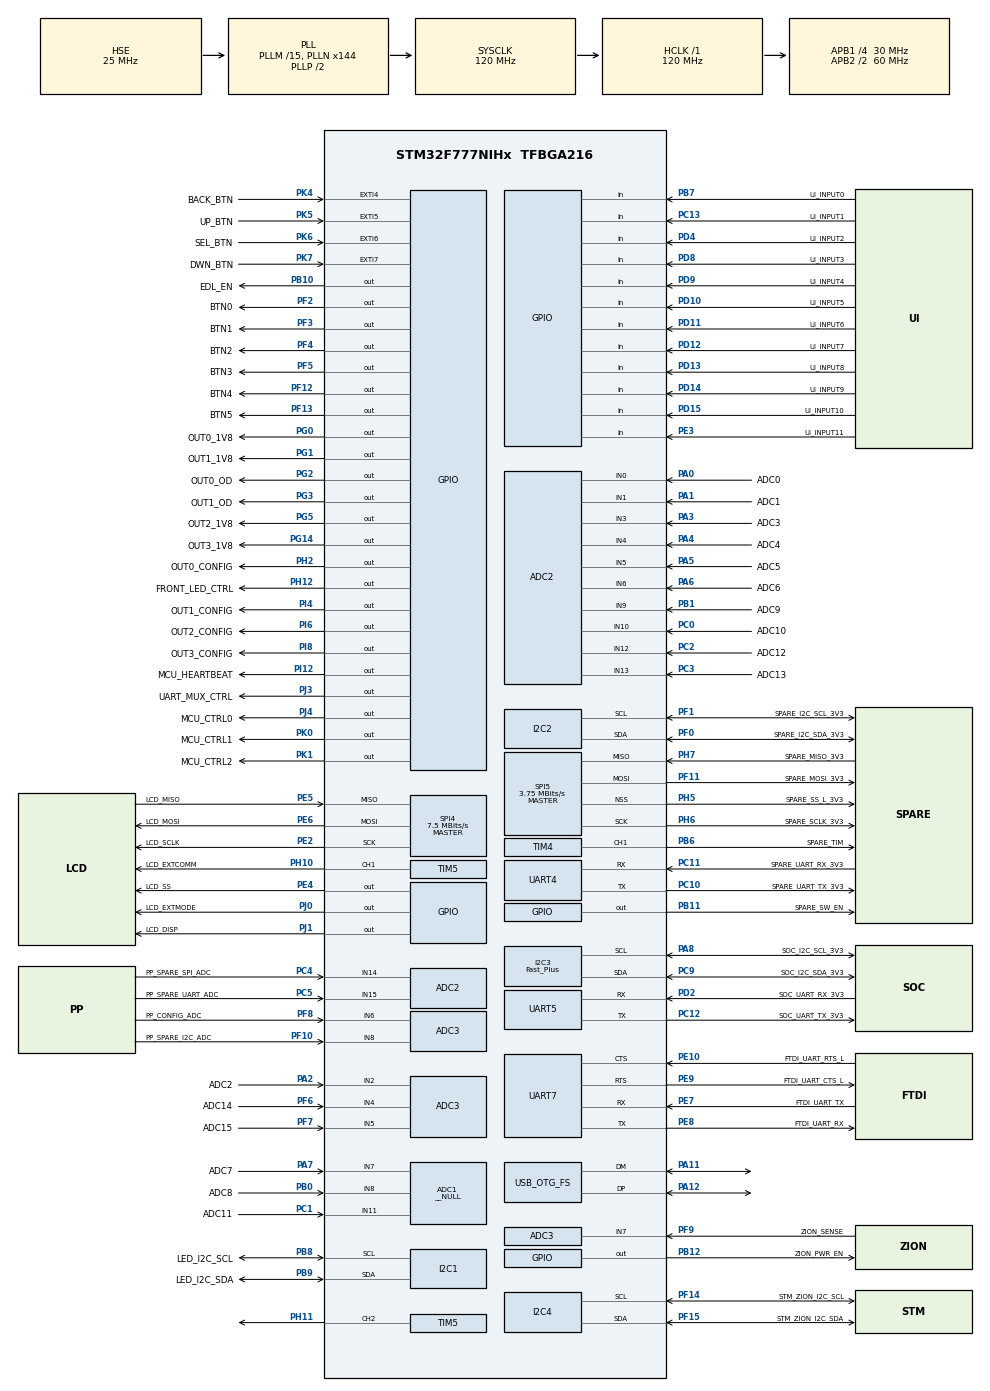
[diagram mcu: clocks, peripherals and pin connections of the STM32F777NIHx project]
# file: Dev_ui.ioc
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ADC1.Channel-0\#ChannelRegularConversion=ADC_CHANNEL_3
ADC1.Channel-1\#ChannelRegularConversion=ADC_CHANNEL_4
ADC1.Channel-10\#ChannelRegularConversion=ADC_CHANNEL_13
ADC1.Channel-2\#ChannelRegularConversion=ADC_CHANNEL_5
ADC1.Channel-3\#ChannelRegularConversion=ADC_CHANNEL_6
ADC1.Channel-4\#ChannelRegularConversion=ADC_CHANNEL_7
ADC1.Channel-5\#ChannelRegularConversion=ADC_CHANNEL_8
ADC1.Channel-6\#ChannelRegularConversion=ADC_CHANNEL_9
ADC1.Channel-7\#ChannelRegularConversion=ADC_CHANNEL_10
ADC1.Channel-8\#ChannelRegularConversion=ADC_CHANNEL_11
ADC1.Channel-9\#ChannelRegularConversion=ADC_CHANNEL_12
ADC1.ClockPrescaler=ADC_CLOCK_SYNC_PCLK_DIV4
ADC1.ContinuousConvMode=ENABLE
ADC1.DMAContinuousRequests=ENABLE
ADC1.InjNumberOfConversion=0
ADC1.Mode=__NULL
ADC1.NbrOfConversion=11
ADC1.NbrOfConversionFlag=1
ADC1.Rank-0\#ChannelRegularConversion=1
ADC1.Rank-1\#ChannelRegularConversion=2
ADC1.Rank-10\#ChannelRegularConversion=11
ADC1.Rank-2\#ChannelRegularConversion=3
ADC1.Rank-3\#ChannelRegularConversion=4
ADC1.Rank-4\#ChannelRegularConversion=5
ADC1.Rank-5\#ChannelRegularConversion=6
ADC1.Rank-6\#ChannelRegularConversion=7
ADC1.Rank-7\#ChannelRegularConversion=8
ADC1.Rank-8\#ChannelRegularConversion=9
ADC1.Rank-9\#ChannelRegularConversion=10
ADC1.SamplingTime-0\#ChannelRegularConversion=ADC_SAMPLETIME_480CYCLES
ADC1.SamplingTime-1\#ChannelRegularConversion=ADC_SAMPLETIME_480CYCLES
ADC1.SamplingTime-10\#ChannelRegularConversion=ADC_SAMPLETIME_480CYCLES
ADC1.SamplingTime-2\#ChannelRegularConversion=ADC_SAMPLETIME_480CYCLES
ADC1.SamplingTime-3\#ChannelRegularConversion=ADC_SAMPLETIME_480CYCLES
ADC1.SamplingTime-4\#ChannelRegularConversion=ADC_SAMPLETIME_480CYCLES
ADC1.SamplingTime-5\#ChannelRegularConversion=ADC_SAMPLETIME_480CYCLES
ADC1.SamplingTime-6\#ChannelRegularConversion=ADC_SAMPLETIME_480CYCLES
ADC1.SamplingTime-7\#ChannelRegularConversion=ADC_SAMPLETIME_480CYCLES
ADC1.SamplingTime-8\#ChannelRegularConversion=ADC_SAMPLETIME_480CYCLES
ADC1.SamplingTime-9\#ChannelRegularConversion=ADC_SAMPLETIME_480CYCLES
ADC1.ScanConvMode=ADC_SCAN_ENABLE
ADC1.master=1
ADC2.Channel-0\#ChannelRegularConversion=ADC_CHANNEL_0
ADC2.Channel-1\#ChannelRegularConversion=ADC_CHANNEL_1
ADC2.Channel-2\#ChannelRegularConversion=ADC_CHANNEL_14
ADC2.Channel-3\#ChannelRegularConversion=ADC_CHANNEL_15
ADC2.ClockPrescaler=ADC_CLOCK_SYNC_PCLK_DIV4
ADC2.ContinuousConvMode=ENABLE
ADC2.DMAContinuousRequests=ENABLE
ADC2.NbrOfConversion=4
ADC2.NbrOfConversionFlag=1
ADC2.Rank-0\#ChannelRegularConversion=1
ADC2.Rank-1\#ChannelRegularConversion=2
ADC2.Rank-2\#ChannelRegularConversion=3
ADC2.Rank-3\#ChannelRegularConversion=4
ADC2.SamplingTime-0\#ChannelRegularConversion=ADC_SAMPLETIME_480CYCLES
ADC2.SamplingTime-1\#ChannelRegularConversion=ADC_SAMPLETIME_480CYCLES
ADC2.SamplingTime-2\#ChannelRegularConversion=ADC_SAMPLETIME_480CYCLES
ADC2.SamplingTime-3\#ChannelRegularConversion=ADC_SAMPLETIME_480CYCLES
ADC2.ScanConvMode=ADC_SCAN_ENABLE
ADC3.Channel-0\#ChannelRegularConversion=ADC_CHANNEL_2
ADC3.Channel-1\#ChannelRegularConversion=ADC_CHANNEL_4
ADC3.Channel-2\#ChannelRegularConversion=ADC_CHANNEL_5
ADC3.Channel-3\#ChannelRegularConversion=ADC_CHANNEL_6
ADC3.Channel-4\#ChannelRegularConversion=ADC_CHANNEL_7
ADC3.Channel-5\#ChannelRegularConversion=ADC_CHANNEL_8
ADC3.ClockPrescaler=ADC_CLOCK_SYNC_PCLK_DIV4
ADC3.ContinuousConvMode=ENABLE
ADC3.DMAContinuousRequests=ENABLE
ADC3.NbrOfConversion=6
ADC3.NbrOfConversionFlag=1
ADC3.Rank-0\#ChannelRegularConversion=1
ADC3.Rank-1\#ChannelRegularConversion=2
ADC3.Rank-2\#ChannelRegularConversion=3
ADC3.Rank-3\#ChannelRegularConversion=4
ADC3.Rank-4\#ChannelRegularConversion=5
ADC3.Rank-5\#ChannelRegularConversion=6
ADC3.SamplingTime-0\#ChannelRegularConversion=ADC_SAMPLETIME_480CYCLES
ADC3.SamplingTime-1\#ChannelRegularConversion=ADC_SAMPLETIME_480CYCLES
ADC3.SamplingTime-2\#ChannelRegularConversion=ADC_SAMPLETIME_480CYCLES
ADC3.SamplingTime-3\#ChannelRegularConversion=ADC_SAMPLETIME_480CYCLES
ADC3.SamplingTime-4\#ChannelRegularConversion=ADC_SAMPLETIME_480CYCLES
ADC3.SamplingTime-5\#ChannelRegularConversion=ADC_SAMPLETIME_480CYCLES
ADC3.ScanConvMode=ADC_SCAN_ENABLE
ADC3.TwoSamplingDelay=ADC_TWOSAMPLINGDELAY_20CYCLES
Dma.ADC1.0.Direction=DMA_PERIPH_TO_MEMORY
Dma.ADC1.0.FIFOMode=DMA_FIFOMODE_DISABLE
Dma.ADC1.0.Instance=DMA2_Stream0
Dma.ADC1.0.MemDataAlignment=DMA_MDATAALIGN_WORD
Dma.ADC1.0.MemInc=DMA_MINC_ENABLE
Dma.ADC1.0.Mode=DMA_NORMAL
Dma.ADC1.0.PeriphDataAlignment=DMA_PDATAALIGN_WORD
Dma.ADC1.0.PeriphInc=DMA_PINC_DISABLE
Dma.ADC1.0.Priority=DMA_PRIORITY_LOW
Dma.ADC2.1.Direction=DMA_PERIPH_TO_MEMORY
Dma.ADC2.1.FIFOMode=DMA_FIFOMODE_DISABLE
Dma.ADC2.1.Instance=DMA2_Stream2
Dma.ADC2.1.MemDataAlignment=DMA_MDATAALIGN_WORD
Dma.ADC2.1.MemInc=DMA_MINC_ENABLE
Dma.ADC2.1.Mode=DMA_NORMAL
Dma.ADC2.1.PeriphDataAlignment=DMA_PDATAALIGN_WORD
Dma.ADC2.1.PeriphInc=DMA_PINC_DISABLE
Dma.ADC2.1.Priority=DMA_PRIORITY_LOW
Dma.ADC3.2.Direction=DMA_PERIPH_TO_MEMORY
Dma.ADC3.2.FIFOMode=DMA_FIFOMODE_DISABLE
Dma.ADC3.2.Instance=DMA2_Stream1
Dma.ADC3.2.MemDataAlignment=DMA_MDATAALIGN_WORD
Dma.ADC3.2.MemInc=DMA_MINC_ENABLE
Dma.ADC3.2.Mode=DMA_NORMAL
Dma.ADC3.2.PeriphDataAlignment=DMA_PDATAALIGN_WORD
Dma.ADC3.2.PeriphInc=DMA_PINC_DISABLE
Dma.ADC3.2.Priority=DMA_PRIORITY_LOW
Dma.Request0=ADC1
Dma.Request1=ADC2
Dma.Request2=ADC3
Dma.Request3=UART5_RX
Dma.Request4=UART7_RX
Dma.Request5=UART4_RX
Dma.UART4_RX.5.Direction=DMA_PERIPH_TO_MEMORY
Dma.UART4_RX.5.FIFOMode=DMA_FIFOMODE_DISABLE
Dma.UART4_RX.5.Instance=DMA1_Stream2
Dma.UART4_RX.5.MemDataAlignment=DMA_MDATAALIGN_BYTE
Dma.UART4_RX.5.MemInc=DMA_MINC_ENABLE
Dma.UART4_RX.5.Mode=DMA_CIRCULAR
Dma.UART4_RX.5.PeriphDataAlignment=DMA_PDATAALIGN_BYTE
Dma.UART4_RX.5.PeriphInc=DMA_PINC_DISABLE
Dma.UART4_RX.5.Priority=DMA_PRIORITY_LOW
Dma.UART5_RX.3.Direction=DMA_PERIPH_TO_MEMORY
Dma.UART5_RX.3.FIFOMode=DMA_FIFOMODE_DISABLE
Dma.UART5_RX.3.Instance=DMA1_Stream0
Dma.UART5_RX.3.MemDataAlignment=DMA_MDATAALIGN_BYTE
Dma.UART5_RX.3.MemInc=DMA_MINC_ENABLE
Dma.UART5_RX.3.Mode=DMA_CIRCULAR
Dma.UART5_RX.3.PeriphDataAlignment=DMA_PDATAALIGN_BYTE
Dma.UART5_RX.3.PeriphInc=DMA_PINC_DISABLE
Dma.UART5_RX.3.Priority=DMA_PRIORITY_LOW
Dma.UART7_RX.4.Direction=DMA_PERIPH_TO_MEMORY
Dma.UART7_RX.4.FIFOMode=DMA_FIFOMODE_DISABLE
Dma.UART7_RX.4.Instance=DMA1_Stream3
Dma.UART7_RX.4.MemDataAlignment=DMA_MDATAALIGN_BYTE
Dma.UART7_RX.4.MemInc=DMA_MINC_ENABLE
Dma.UART7_RX.4.Mode=DMA_CIRCULAR
Dma.UART7_RX.4.PeriphDataAlignment=DMA_PDATAALIGN_BYTE
Dma.UART7_RX.4.PeriphInc=DMA_PINC_DISABLE
Dma.UART7_RX.4.Priority=DMA_PRIORITY_LOW
FREERTOS.Events01=Fault_Events,Dynamic,NULL
FREERTOS.Tasks01=Heartbeat,32,256,startHeartbeat,Default,NULL,Dynamic,NULL,NULL;adcRead,9,256,startADCRead,Default,NULL,Dynamic,NULL,NULL;DatScreenBlink,26,5000,GetDaScreenBlink,Default,NULL,Dynamic,NULL,NULL;gpioInputRead,10,256,startGpioInputRead,Default,NULL,Dynamic,NULL,NULL;navigationTask,42,1000,startNavigationTask,Default,NULL,Dynamic,NULL,NULL;errorLEDs,13,1024,startErrorLEDs,Default,NULL,Dynamic,NULL,NULL;zionRead,41,2000,startZionRead,Default,NULL,Dynamic,NULL,NULL;bootButtons,22,1024,startBootButtons,Default,NULL,Dynamic,NULL,NULL;socUart,15,1024,startSocUart,Default,NULL,Dynamic,NULL,NULL;debugUart,15,512,startDebugUart,Default,NULL,Dynamic,NULL,NULL
FREERTOS.configTOTAL_HEAP_SIZE=150000
I2C1.Timing=0x007074AF
I2C2.Timing=0x007074AF
I2C3.I2C_Speed_Mode=I2C_Fast_Plus
I2C3.OwnAddress=76
I2C3.Speed=50
I2C3.Timing=0x100029FE
I2C4.Timing=0x007074AF
Mcu.Family=STM32F7
Mcu.Name=STM32F777NIHx
Mcu.Package=TFBGA216
NVIC.ADC_IRQn=true\:5\:0\:false\:false\:true\:true\:true\:true
NVIC.DMA1_Stream0_IRQn=true\:5\:0\:false\:false\:true\:true\:false\:true
NVIC.DMA1_Stream2_IRQn=true\:5\:0\:false\:false\:true\:true\:false\:true
NVIC.DMA1_Stream3_IRQn=true\:5\:0\:false\:false\:true\:true\:false\:true
NVIC.DMA2_Stream0_IRQn=true\:5\:0\:false\:false\:true\:true\:false\:true
NVIC.DMA2_Stream1_IRQn=true\:5\:0\:false\:false\:true\:true\:false\:true
NVIC.DMA2_Stream2_IRQn=true\:5\:0\:false\:false\:true\:true\:false\:true
NVIC.EXTI4_IRQn=true\:5\:0\:false\:false\:true\:true\:true\:true
NVIC.EXTI9_5_IRQn=true\:5\:0\:false\:false\:true\:true\:true\:true
NVIC.PriorityGroup=NVIC_PRIORITYGROUP_4
NVIC.SPI4_IRQn=true\:5\:0\:false\:false\:true\:true\:true\:true
NVIC.TIM6_DAC_IRQn=true\:0\:0\:false\:false\:true\:false\:false\:true
NVIC.TimeBase=TIM6_DAC_IRQn
NVIC.TimeBaseIP=TIM6
PA0/WKUP.GPIO_Label=ADC0
PA0/WKUP.Signal=ADCx_IN0
PA1.GPIO_Label=ADC1
PA1.Signal=ADCx_IN1
PA10.Signal=USB_OTG_FS_ID
PA11.Mode=Device_Only
PA11.Signal=USB_OTG_FS_DM
PA12.Mode=Device_Only
PA12.Signal=USB_OTG_FS_DP
PA13.Mode=JTAG_5_pins
PA13.Signal=SYS_JTMS-SWDIO
PA14.Mode=JTAG_5_pins
PA14.Signal=SYS_JTCK-SWCLK
PA15.Mode=JTAG_5_pins
PA15.Signal=SYS_JTDI
PA2.GPIO_Label=ADC2
PA2.Signal=ADCx_IN2
PA3.GPIO_Label=ADC3
PA3.GPIO_Mode=GPIO_MODE_ANALOG
PA3.GPIO_PuPd=GPIO_NOPULL
PA3.Signal=ADCx_IN3
PA4.GPIO_Label=ADC4
PA4.GPIO_Mode=GPIO_MODE_ANALOG
PA4.GPIO_PuPd=GPIO_NOPULL
PA4.Signal=ADCx_IN4
PA5.GPIO_Label=ADC5
PA5.GPIO_Mode=GPIO_MODE_ANALOG
PA5.GPIO_PuPd=GPIO_NOPULL
PA5.Signal=ADCx_IN5
PA6.GPIO_Label=ADC6
PA6.GPIO_Mode=GPIO_MODE_ANALOG
PA6.GPIO_PuPd=GPIO_NOPULL
PA6.Signal=ADCx_IN6
PA7.GPIO_Label=ADC7
PA7.Signal=ADCx_IN7
PA8.GPIO_Label=SOC_I2C_SCL_3V3
PA8.GPIO_Mode=GPIO_MODE_AF_OD
PA8.GPIO_PuPdOD=GPIO_PULLUP
PA8.GPIO_Speed=GPIO_SPEED_FREQ_VERY_HIGH
PA8.Mode=I2C
PA8.Signal=I2C3_SCL
PB0.GPIO_Label=ADC8
PB0.Signal=ADCx_IN8
PB1.GPIO_Label=ADC9
PB1.GPIO_Mode=GPIO_MODE_ANALOG
PB1.GPIO_PuPd=GPIO_NOPULL
PB1.Signal=ADCx_IN9
PB10.GPIO_Label=EDL_EN
PB10.Signal=GPIO_Output
PB11.GPIO_Label=SPARE_SW_EN
PB11.Signal=GPIO_Output
PB12.GPIO_Label=ZION_PWR_EN
PB12.Signal=GPIO_Output
PB3.Mode=JTAG_5_pins
PB3.Signal=SYS_JTDO-SWO
PB4.Mode=JTAG_5_pins
PB4.Signal=SYS_JTRST
PB6.GPIO_Label=SPARE_TIM
PB6.Signal=S_TIM4_CH1
PB7.GPIO_Label=UI_INPUT0
PB7.GPIO_Mode=GPIO_MODE_INPUT
PB7.GPIO_PuPd=GPIO_NOPULL
PB7.Signal=GPIO_Input
PB8.GPIO_Label=LED_I2C_SCL
PB8.GPIO_Mode=GPIO_MODE_AF_OD
PB8.GPIO_PuPdOD=GPIO_PULLUP
PB8.GPIO_Speed=GPIO_SPEED_FREQ_VERY_HIGH
PB8.Mode=I2C
PB8.Signal=I2C1_SCL
PB9.GPIO_Label=LED_I2C_SDA
PB9.GPIO_Mode=GPIO_MODE_AF_OD
PB9.GPIO_PuPdOD=GPIO_PULLUP
PB9.GPIO_Speed=GPIO_SPEED_FREQ_VERY_HIGH
PB9.Mode=I2C
PB9.Signal=I2C1_SDA
PC0.GPIO_Label=ADC10
PC0.GPIO_Mode=GPIO_MODE_ANALOG
PC0.GPIO_PuPd=GPIO_NOPULL
PC0.Signal=ADCx_IN10
PC1.GPIO_Label=ADC11
PC1.Signal=ADCx_IN11
PC10.GPIO_Label=SPARE_UART_TX_3V3
PC10.GPIO_ModeDefaultPP=GPIO_MODE_AF_PP
PC10.GPIO_PuPd=GPIO_NOPULL
PC10.GPIO_Speed=GPIO_SPEED_FREQ_VERY_HIGH
PC10.Mode=Asynchronous
PC10.Signal=UART4_TX
PC11.GPIO_Label=SPARE_UART_RX_3V3
PC11.GPIO_ModeDefaultPP=GPIO_MODE_AF_PP
PC11.GPIO_PuPd=GPIO_NOPULL
PC11.GPIO_Speed=GPIO_SPEED_FREQ_VERY_HIGH
PC11.Mode=Asynchronous
PC11.Signal=UART4_RX
PC12.GPIO_Label=SOC_UART_TX_3V3
PC12.GPIO_ModeDefaultPP=GPIO_MODE_AF_PP
PC12.GPIO_PuPd=GPIO_NOPULL
PC12.GPIO_Speed=GPIO_SPEED_FREQ_VERY_HIGH
PC12.Mode=Asynchronous
PC12.Signal=UART5_TX
PC13.GPIO_Label=UI_INPUT1
PC13.GPIO_Mode=GPIO_MODE_INPUT
PC13.GPIO_PuPd=GPIO_NOPULL
PC13.Signal=GPIO_Input
PC14/OSC32_IN.Mode=LSE-External-Oscillator
PC14/OSC32_IN.Signal=RCC_OSC32_IN
PC15/OSC32_OUT.Mode=LSE-External-Oscillator
PC15/OSC32_OUT.Signal=RCC_OSC32_OUT
PC2.GPIO_Label=ADC12
PC2.GPIO_Mode=GPIO_MODE_ANALOG
PC2.GPIO_PuPd=GPIO_NOPULL
PC2.Signal=ADCx_IN12
PC3.GPIO_Label=ADC13
PC3.GPIO_Mode=GPIO_MODE_ANALOG
PC3.GPIO_PuPd=GPIO_NOPULL
PC3.Signal=ADCx_IN13
PC4.GPIO_Label=PP_SPARE_SPI_ADC
PC4.Signal=ADCx_IN14
PC5.GPIO_Label=PP_SPARE_UART_ADC
PC5.Signal=ADCx_IN15
PC9.GPIO_Label=SOC_I2C_SDA_3V3
PC9.GPIO_Mode=GPIO_MODE_AF_OD
PC9.GPIO_PuPdOD=GPIO_PULLUP
PC9.GPIO_Speed=GPIO_SPEED_FREQ_VERY_HIGH
PC9.Mode=I2C
PC9.Signal=I2C3_SDA
PD10.GPIO_Label=UI_INPUT5
PD10.GPIO_Mode=GPIO_MODE_INPUT
PD10.GPIO_PuPd=GPIO_NOPULL
PD10.Signal=GPIO_Input
PD11.GPIO_Label=UI_INPUT6
PD11.GPIO_Mode=GPIO_MODE_INPUT
PD11.GPIO_PuPd=GPIO_NOPULL
PD11.Signal=GPIO_Input
PD12.GPIO_Label=UI_INPUT7
PD12.GPIO_Mode=GPIO_MODE_INPUT
PD12.GPIO_PuPd=GPIO_NOPULL
PD12.Signal=GPIO_Input
PD13.GPIO_Label=UI_INPUT8
PD13.GPIO_Mode=GPIO_MODE_INPUT
PD13.GPIO_PuPd=GPIO_NOPULL
PD13.Signal=GPIO_Input
PD14.GPIO_Label=UI_INPUT9
PD14.GPIO_Mode=GPIO_MODE_INPUT
PD14.GPIO_PuPd=GPIO_NOPULL
PD14.Signal=GPIO_Input
PD15.GPIO_Label=UI_INPUT10
PD15.GPIO_Mode=GPIO_MODE_INPUT
PD15.GPIO_PuPd=GPIO_NOPULL
PD15.Signal=GPIO_Input
PD2.GPIO_Label=SOC_UART_RX_3V3
PD2.GPIO_ModeDefaultPP=GPIO_MODE_AF_PP
PD2.GPIO_PuPd=GPIO_NOPULL
PD2.GPIO_Speed=GPIO_SPEED_FREQ_VERY_HIGH
PD2.Mode=Asynchronous
PD2.Signal=UART5_RX
PD4.GPIO_Label=UI_INPUT2
PD4.GPIO_Mode=GPIO_MODE_INPUT
PD4.GPIO_PuPd=GPIO_NOPULL
PD4.Signal=GPIO_Input
PD8.GPIO_Label=UI_INPUT3
PD8.GPIO_Mode=GPIO_MODE_INPUT
PD8.GPIO_PuPd=GPIO_NOPULL
PD8.Signal=GPIO_Input
PD9.GPIO_Label=UI_INPUT4
PD9.GPIO_Mode=GPIO_MODE_INPUT
PD9.GPIO_PuPd=GPIO_NOPULL
PD9.Signal=GPIO_Input
PE10.GPIO_Label=FTDI_UART_RTS_L
PE10.GPIO_Mode=GPIO_MODE_AF_PP
PE10.GPIO_PuPd=GPIO_NOPULL
PE10.GPIO_Speed=GPIO_SPEED_FREQ_VERY_HIGH
PE10.Mode=CTS_RTS
PE10.Signal=UART7_CTS
PE2.GPIO_Label=LCD_SCLK
PE2.GPIO_Mode=GPIO_MODE_AF_PP
PE2.GPIO_PuPd=GPIO_NOPULL
PE2.GPIO_Speed=GPIO_SPEED_FREQ_VERY_HIGH
PE2.Mode=Full_Duplex_Master
PE2.Signal=SPI4_SCK
PE3.GPIO_Label=UI_INPUT11
PE3.GPIO_Mode=GPIO_MODE_INPUT
PE3.GPIO_PuPd=GPIO_NOPULL
PE3.Signal=GPIO_Input
PE4.GPIO_Label=LCD_SS
PE4.GPIO_Speed=GPIO_SPEED_FREQ_HIGH
PE4.Signal=GPIO_Output
PE5.GPIO_Label=LCD_MISO
PE5.GPIO_Mode=GPIO_MODE_AF_PP
PE5.GPIO_PuPd=GPIO_NOPULL
PE5.GPIO_Speed=GPIO_SPEED_FREQ_VERY_HIGH
PE5.Mode=Full_Duplex_Master
PE5.Signal=SPI4_MISO
PE6.GPIO_Label=LCD_MOSI
PE6.GPIO_Mode=GPIO_MODE_AF_PP
PE6.GPIO_PuPd=GPIO_NOPULL
PE6.GPIO_Speed=GPIO_SPEED_FREQ_VERY_HIGH
PE6.Mode=Full_Duplex_Master
PE6.Signal=SPI4_MOSI
PE7.GPIO_Label=FTDI_UART_TX
PE7.GPIO_ModeDefaultPP=GPIO_MODE_AF_PP
PE7.GPIO_PuPd=GPIO_NOPULL
PE7.GPIO_Speed=GPIO_SPEED_FREQ_VERY_HIGH
PE7.Mode=Asynchronous
PE7.Signal=UART7_RX
PE8.GPIO_Label=FTDI_UART_RX
PE8.GPIO_ModeDefaultPP=GPIO_MODE_AF_PP
PE8.GPIO_PuPd=GPIO_NOPULL
PE8.GPIO_Speed=GPIO_SPEED_FREQ_VERY_HIGH
PE8.Mode=Asynchronous
PE8.Signal=UART7_TX
PE9.GPIO_Label=FTDI_UART_CTS_L
PE9.GPIO_Mode=GPIO_MODE_AF_PP
PE9.GPIO_PuPd=GPIO_NOPULL
PE9.GPIO_Speed=GPIO_SPEED_FREQ_VERY_HIGH
PE9.Mode=CTS_RTS
PE9.Signal=UART7_RTS
PF0.GPIO_Label=SPARE_I2C_SDA_3V3
PF0.GPIO_Mode=GPIO_MODE_AF_OD
PF0.GPIO_PuPdOD=GPIO_PULLUP
PF0.GPIO_Speed=GPIO_SPEED_FREQ_VERY_HIGH
PF0.Mode=I2C
PF0.Signal=I2C2_SDA
PF1.GPIO_Label=SPARE_I2C_SCL_3V3
PF1.GPIO_Mode=GPIO_MODE_AF_OD
PF1.GPIO_PuPdOD=GPIO_PULLUP
PF1.GPIO_Speed=GPIO_SPEED_FREQ_VERY_HIGH
PF1.Mode=I2C
PF1.Signal=I2C2_SCL
PF10.GPIO_Label=PP_SPARE_I2C_ADC
PF10.Mode=IN8
PF10.Signal=ADC3_IN8
PF11.GPIO_Label=SPARE_MOSI_3V3
PF11.GPIO_Mode=GPIO_MODE_AF_PP
PF11.GPIO_PuPd=GPIO_NOPULL
PF11.GPIO_Speed=GPIO_SPEED_FREQ_VERY_HIGH
PF11.Mode=Full_Duplex_Master
PF11.Signal=SPI5_MOSI
PF12.GPIO_Label=BTN4
PF12.GPIO_ModeDefaultOutputPP=GPIO_MODE_OUTPUT_PP
PF12.GPIO_PuPd=GPIO_NOPULL
PF12.GPIO_Speed=GPIO_SPEED_FREQ_LOW
PF12.PinState=GPIO_PIN_RESET
PF12.Signal=GPIO_Output
PF13.GPIO_Label=BTN5
PF13.GPIO_ModeDefaultOutputPP=GPIO_MODE_OUTPUT_PP
PF13.GPIO_PuPd=GPIO_NOPULL
PF13.GPIO_Speed=GPIO_SPEED_FREQ_LOW
PF13.PinState=GPIO_PIN_RESET
PF13.Signal=GPIO_Output
PF14.GPIO_Label=STM_ZION_I2C_SCL
PF14.GPIO_Mode=GPIO_MODE_AF_OD
PF14.GPIO_PuPdOD=GPIO_PULLUP
PF14.GPIO_Speed=GPIO_SPEED_FREQ_VERY_HIGH
PF14.Mode=I2C
PF14.Signal=I2C4_SCL
PF15.GPIO_Label=STM_ZION_I2C_SDA
PF15.GPIO_Mode=GPIO_MODE_AF_OD
PF15.GPIO_PuPdOD=GPIO_PULLUP
PF15.GPIO_Speed=GPIO_SPEED_FREQ_VERY_HIGH
PF15.Mode=I2C
PF15.Signal=I2C4_SDA
PF2.GPIO_Label=BTN0
PF2.GPIO_ModeDefaultOutputPP=GPIO_MODE_OUTPUT_PP
PF2.GPIO_PuPd=GPIO_NOPULL
PF2.GPIO_Speed=GPIO_SPEED_FREQ_LOW
PF2.PinState=GPIO_PIN_RESET
PF2.Signal=GPIO_Output
PF3.GPIO_Label=BTN1
PF3.GPIO_ModeDefaultOutputPP=GPIO_MODE_OUTPUT_PP
PF3.GPIO_PuPd=GPIO_NOPULL
PF3.GPIO_Speed=GPIO_SPEED_FREQ_LOW
PF3.PinState=GPIO_PIN_RESET
PF3.Signal=GPIO_Output
PF4.GPIO_Label=BTN2
PF4.GPIO_ModeDefaultOutputPP=GPIO_MODE_OUTPUT_PP
PF4.GPIO_PuPd=GPIO_NOPULL
PF4.GPIO_Speed=GPIO_SPEED_FREQ_LOW
PF4.PinState=GPIO_PIN_RESET
PF4.Signal=GPIO_Output
PF5.GPIO_Label=BTN3
PF5.GPIO_ModeDefaultOutputPP=GPIO_MODE_OUTPUT_PP
PF5.GPIO_PuPd=GPIO_NOPULL
PF5.GPIO_Speed=GPIO_SPEED_FREQ_LOW
PF5.PinState=GPIO_PIN_RESET
PF5.Signal=GPIO_Output
PF6.GPIO_Label=ADC14
PF6.GPIO_Mode=GPIO_MODE_ANALOG
PF6.GPIO_PuPd=GPIO_NOPULL
PF6.Mode=IN4
PF6.Signal=ADC3_IN4
PF7.GPIO_Label=ADC15
PF7.GPIO_Mode=GPIO_MODE_ANALOG
PF7.GPIO_PuPd=GPIO_NOPULL
PF7.Mode=IN5
PF7.Signal=ADC3_IN5
PF8.GPIO_Label=PP_CONFIG_ADC
PF8.GPIO_Mode=GPIO_MODE_ANALOG
PF8.GPIO_PuPd=GPIO_NOPULL
PF8.Mode=IN6
PF8.Signal=ADC3_IN6
PF9.GPIO_Label=ZION_SENSE
PF9.GPIO_Mode=GPIO_MODE_ANALOG
PF9.GPIO_PuPd=GPIO_NOPULL
PF9.Mode=IN7
PF9.Signal=ADC3_IN7
PG0.GPIO_Label=OUT0_1V8
PG0.GPIO_ModeDefaultOutputPP=GPIO_MODE_OUTPUT_PP
PG0.GPIO_PuPd=GPIO_NOPULL
PG0.GPIO_Speed=GPIO_SPEED_FREQ_LOW
PG0.PinState=GPIO_PIN_RESET
PG0.Signal=GPIO_Output
PG1.GPIO_Label=OUT1_1V8
PG1.GPIO_ModeDefaultOutputPP=GPIO_MODE_OUTPUT_PP
PG1.GPIO_PuPd=GPIO_NOPULL
PG1.GPIO_Speed=GPIO_SPEED_FREQ_LOW
PG1.PinState=GPIO_PIN_RESET
PG1.Signal=GPIO_Output
PG14.GPIO_Label=OUT3_1V8
PG14.GPIO_ModeDefaultOutputPP=GPIO_MODE_OUTPUT_PP
PG14.GPIO_PuPd=GPIO_NOPULL
PG14.GPIO_Speed=GPIO_SPEED_FREQ_LOW
PG14.PinState=GPIO_PIN_RESET
PG14.Signal=GPIO_Output
PG2.GPIO_Label=OUT0_OD
PG2.Signal=GPIO_Output
PG3.GPIO_Label=OUT1_OD
PG3.Signal=GPIO_Output
PG5.GPIO_Label=OUT2_1V8
PG5.GPIO_ModeDefaultOutputPP=GPIO_MODE_OUTPUT_PP
PG5.GPIO_PuPd=GPIO_NOPULL
PG5.GPIO_Speed=GPIO_SPEED_FREQ_LOW
PG5.PinState=GPIO_PIN_RESET
PG5.Signal=GPIO_Output
PH0/OSC_IN.Mode=HSE-External-Oscillator
PH0/OSC_IN.Signal=RCC_OSC_IN
PH1/OSC_OUT.Mode=HSE-External-Oscillator
PH1/OSC_OUT.Signal=RCC_OSC_OUT
PH10.GPIO_Label=LCD_EXTCOMM
PH10.Signal=S_TIM5_CH1
PH11.Signal=S_TIM5_CH2
PH12.GPIO_Label=FRONT_LED_CTRL
PH12.Signal=GPIO_Output
PH2.GPIO_Label=OUT0_CONFIG
PH2.GPIO_ModeDefaultOutputPP=GPIO_MODE_OUTPUT_PP
PH2.GPIO_PuPd=GPIO_NOPULL
PH2.GPIO_Speed=GPIO_SPEED_FREQ_LOW
PH2.PinState=GPIO_PIN_RESET
PH2.Signal=GPIO_Output
PH5.GPIO_Label=SPARE_SS_L_3V3
PH5.GPIO_Mode=GPIO_MODE_AF_PP
PH5.GPIO_PuPd=GPIO_NOPULL
PH5.GPIO_Speed=GPIO_SPEED_FREQ_VERY_HIGH
PH5.Mode=NSS_Signal_Hard_Output
PH5.Signal=SPI5_NSS
PH6.GPIO_Label=SPARE_SCLK_3V3
PH6.GPIO_Mode=GPIO_MODE_AF_PP
PH6.GPIO_PuPd=GPIO_NOPULL
PH6.GPIO_Speed=GPIO_SPEED_FREQ_VERY_HIGH
PH6.Mode=Full_Duplex_Master
PH6.Signal=SPI5_SCK
PH7.GPIO_Label=SPARE_MISO_3V3
PH7.GPIO_Mode=GPIO_MODE_AF_PP
PH7.GPIO_PuPd=GPIO_NOPULL
PH7.GPIO_Speed=GPIO_SPEED_FREQ_VERY_HIGH
PH7.Mode=Full_Duplex_Master
PH7.Signal=SPI5_MISO
PI12.GPIO_Label=MCU_HEARTBEAT
PI12.GPIO_ModeDefaultOutputPP=GPIO_MODE_OUTPUT_PP
PI12.GPIO_PuPd=GPIO_NOPULL
PI12.GPIO_Speed=GPIO_SPEED_FREQ_LOW
PI12.PinState=GPIO_PIN_RESET
PI12.Signal=GPIO_Output
PI4.GPIO_Label=OUT1_CONFIG
PI4.GPIO_ModeDefaultOutputPP=GPIO_MODE_OUTPUT_PP
PI4.GPIO_PuPd=GPIO_NOPULL
PI4.GPIO_Speed=GPIO_SPEED_FREQ_LOW
PI4.PinState=GPIO_PIN_RESET
PI4.Signal=GPIO_Output
PI6.GPIO_Label=OUT2_CONFIG
PI6.GPIO_ModeDefaultOutputPP=GPIO_MODE_OUTPUT_PP
PI6.GPIO_PuPd=GPIO_NOPULL
PI6.GPIO_Speed=GPIO_SPEED_FREQ_LOW
PI6.PinState=GPIO_PIN_RESET
PI6.Signal=GPIO_Output
PI8.GPIO_Label=OUT3_CONFIG
PI8.GPIO_ModeDefaultOutputPP=GPIO_MODE_OUTPUT_PP
PI8.GPIO_PuPd=GPIO_NOPULL
PI8.GPIO_Speed=GPIO_SPEED_FREQ_LOW
PI8.PinState=GPIO_PIN_RESET
PI8.Signal=GPIO_Output
PJ0.GPIO_Label=LCD_EXTMODE
PJ0.GPIO_ModeDefaultOutputPP=GPIO_MODE_OUTPUT_PP
PJ0.GPIO_PuPd=GPIO_NOPULL
PJ0.GPIO_Speed=GPIO_SPEED_FREQ_LOW
PJ0.PinState=GPIO_PIN_RESET
PJ0.Signal=GPIO_Output
PJ1.GPIO_Label=LCD_DISP
PJ1.GPIO_ModeDefaultOutputPP=GPIO_MODE_OUTPUT_PP
PJ1.GPIO_PuPd=GPIO_NOPULL
PJ1.GPIO_Speed=GPIO_SPEED_FREQ_LOW
PJ1.PinState=GPIO_PIN_RESET
PJ1.Signal=GPIO_Output
PJ3.GPIO_Label=UART_MUX_CTRL
PJ3.GPIO_ModeDefaultOutputPP=GPIO_MODE_OUTPUT_PP
PJ3.GPIO_PuPd=GPIO_NOPULL
PJ3.GPIO_Speed=GPIO_SPEED_FREQ_LOW
PJ3.PinState=GPIO_PIN_RESET
PJ3.Signal=GPIO_Output
PJ4.GPIO_Label=MCU_CTRL0
PJ4.GPIO_ModeDefaultOutputPP=GPIO_MODE_OUTPUT_PP
PJ4.GPIO_PuPd=GPIO_NOPULL
PJ4.GPIO_Speed=GPIO_SPEED_FREQ_LOW
PJ4.PinState=GPIO_PIN_RESET
PJ4.Signal=GPIO_Output
PK0.GPIO_Label=MCU_CTRL1
PK0.GPIO_ModeDefaultOutputPP=GPIO_MODE_OUTPUT_PP
PK0.GPIO_PuPd=GPIO_NOPULL
PK0.GPIO_Speed=GPIO_SPEED_FREQ_LOW
PK0.PinState=GPIO_PIN_RESET
PK0.Signal=GPIO_Output
PK1.GPIO_Label=MCU_CTRL2
PK1.GPIO_ModeDefaultOutputPP=GPIO_MODE_OUTPUT_PP
PK1.GPIO_PuPd=GPIO_NOPULL
PK1.GPIO_Speed=GPIO_SPEED_FREQ_LOW
PK1.PinState=GPIO_PIN_RESET
PK1.Signal=GPIO_Output
PK4.GPIO_Label=BACK_BTN
PK4.GPIO_ModeDefaultEXTI=GPIO_MODE_IT_FALLING
PK4.Signal=GPXTI4
PK5.GPIO_Label=UP_BTN
PK5.GPIO_ModeDefaultEXTI=GPIO_MODE_IT_FALLING
PK5.Signal=GPXTI5
PK6.GPIO_Label=SEL_BTN
PK6.GPIO_ModeDefaultEXTI=GPIO_MODE_IT_FALLING
PK6.Signal=GPXTI6
PK7.GPIO_Label=DWN_BTN
PK7.GPIO_ModeDefaultEXTI=GPIO_MODE_IT_FALLING
PK7.Signal=GPXTI7
ProjectManager.HeapSize=0x200
ProjectManager.StackSize=0x400
ProjectManager.TargetToolchain=STM32CubeIDE
RCC.AHBFreq_Value=120000000
RCC.APB1CLKDivider=RCC_HCLK_DIV4
RCC.APB1Freq_Value=30000000
RCC.APB1TimFreq_Value=60000000
RCC.APB2CLKDivider=RCC_HCLK_DIV2
RCC.APB2Freq_Value=60000000
RCC.APB2TimFreq_Value=120000000
RCC.CortexFreq_Value=120000000
RCC.HCLKFreq_Value=120000000
RCC.HSE_VALUE=25000000
RCC.HSI_VALUE=16000000
RCC.PLLM=15
RCC.PLLN=144
RCC.PLLQ=5
RCC.PLLSAIN=60
RCC.RTCClockSelection=RCC_RTCCLKSOURCE_LSE
RCC.SYSCLKFreq_VALUE=120000000
RCC.SYSCLKSource=RCC_SYSCLKSOURCE_PLLCLK
RCC.USBFreq_Value=48000000
RCC.VCOOutputFreq_Value=240000000
SH.ADCx_IN0.0=ADC2_IN0,IN0
SH.ADCx_IN1.0=ADC2_IN1,IN1
SH.ADCx_IN10.0=ADC2_IN10,IN10
SH.ADCx_IN10.1=ADC1_IN10,IN10
SH.ADCx_IN10.2=ADC3_IN10,IN10
SH.ADCx_IN11.0=ADC2_IN11
SH.ADCx_IN11.1=ADC3_IN11
SH.ADCx_IN11.2=ADC1_IN11,IN11
SH.ADCx_IN12.0=ADC2_IN12,IN12
SH.ADCx_IN12.1=ADC1_IN12,IN12
SH.ADCx_IN12.2=ADC3_IN12,IN12
SH.ADCx_IN13.0=ADC2_IN13,IN13
SH.ADCx_IN13.1=ADC1_IN13,IN13
SH.ADCx_IN13.2=ADC3_IN13,IN13
SH.ADCx_IN14.0=ADC2_IN14,IN14
SH.ADCx_IN15.0=ADC2_IN15,IN15
SH.ADCx_IN2.0=ADC3_IN2,IN2
SH.ADCx_IN3.0=ADC2_IN3,IN3
SH.ADCx_IN3.1=ADC1_IN3,IN3
SH.ADCx_IN3.2=ADC3_IN3,IN3
SH.ADCx_IN4.0=ADC2_IN4,IN4
SH.ADCx_IN4.1=ADC1_IN4,IN4
SH.ADCx_IN5.0=ADC2_IN5,IN5
SH.ADCx_IN5.1=ADC1_IN5,IN5
SH.ADCx_IN6.0=ADC2_IN6,IN6
SH.ADCx_IN6.1=ADC1_IN6,IN6
SH.ADCx_IN7.0=ADC1_IN7,IN7
SH.ADCx_IN8.0=ADC1_IN8,IN8
SH.ADCx_IN9.0=ADC2_IN9,IN9
SH.ADCx_IN9.1=ADC1_IN9,IN9
SH.S_TIM4_CH1.0=TIM4_CH1,PWM Generation1 CH1
SH.S_TIM5_CH1.0=TIM5_CH1,PWM Generation1 CH1
SH.S_TIM5_CH2.0=TIM5_CH2,PWM Generation2 CH2
SPI4.BaudRatePrescaler=SPI_BAUDRATEPRESCALER_8
SPI4.CalculateBaudRate=7.5 MBits/s
SPI4.DataSize=SPI_DATASIZE_8BIT
SPI4.Direction=SPI_DIRECTION_2LINES
SPI4.Mode=SPI_MODE_MASTER
SPI4.NSSPMode=SPI_NSS_PULSE_DISABLE
SPI4.VirtualType=VM_MASTER
SPI5.BaudRatePrescaler=SPI_BAUDRATEPRESCALER_16
SPI5.CalculateBaudRate=3.75 MBits/s
SPI5.DataSize=SPI_DATASIZE_8BIT
SPI5.Direction=SPI_DIRECTION_2LINES
SPI5.Mode=SPI_MODE_MASTER
SPI5.NSSPMode=SPI_NSS_PULSE_DISABLE
SPI5.VirtualNSS=VM_NSSHARD
SPI5.VirtualType=VM_MASTER
TIM4.Channel-PWM\ Generation1\ CH1=TIM_CHANNEL_1
TIM5.Channel-PWM\ Generation1\ CH1=TIM_CHANNEL_1
TIM5.Channel-PWM\ Generation2\ CH2=TIM_CHANNEL_2
USB_OTG_FS.VirtualMode=Device_Only
VP_FREERTOS_VS_CMSIS_V2.Mode=CMSIS_V2
VP_RTC_VS_RTC_Activate.Mode=RTC_Enabled
VP_SYS_VS_tim6.Mode=TIM6
VP_TIM4_VS_ClockSourceINT.Mode=Internal
VP_TIM5_VS_ClockSourceINT.Mode=Internal
board=custom

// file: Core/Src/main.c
/* USER CODE BEGIN Header */
/**
  ******************************************************************************
  * @file           : main.c
  * @brief          : Main program body
  ******************************************************************************
  * @attention
  *
  * <h2><center>&copy; Copyright (c) 2021 STMicroelectronics.
  * All rights reserved.</center></h2>
  *
  * This software component is licensed by ST under BSD 3-Clause license,
  * the "License"; You may not use this file except in compliance with the
  * License. You may obtain a copy of the License at:
  *                        opensource.org/licenses/BSD-3-Clause
  *
  ******************************************************************************
  */
/* USER CODE END Header */
#include "main.h"
#include "cmsis_os.h"

/* USER CODE BEGIN PTD */
//ADC Definitions
#define ADC_BUF_LEN 			5000
#define ADC_AVG_COUNT 			20

//UART Buffer Length Definitions
#define SOC_UART_BUF_LEN		1000
#define SPARE_UART_BUF_LEN		200
#define DEBUG_UART_BUF_LEN		200

/* USER CODE END PTD */

ADC_HandleTypeDef hadc1;
ADC_HandleTypeDef hadc2;
ADC_HandleTypeDef hadc3;
DMA_HandleTypeDef hdma_adc1;
DMA_HandleTypeDef hdma_adc2;
DMA_HandleTypeDef hdma_adc3;

I2C_HandleTypeDef hi2c1;
I2C_HandleTypeDef hi2c2;
I2C_HandleTypeDef hi2c3;
I2C_HandleTypeDef hi2c4;

RTC_HandleTypeDef hrtc;

SPI_HandleTypeDef hspi4;
SPI_HandleTypeDef hspi5;

TIM_HandleTypeDef htim4;
TIM_HandleTypeDef htim5;

UART_HandleTypeDef huart4;
UART_HandleTypeDef huart5;
UART_HandleTypeDef huart7;
DMA_HandleTypeDef hdma_uart4_rx;
DMA_HandleTypeDef hdma_uart5_rx;
DMA_HandleTypeDef hdma_uart7_rx;

PCD_HandleTypeDef hpcd_USB_OTG_FS;

/* Definitions for Heartbeat */
osThreadId_t HeartbeatHandle;
const osThreadAttr_t Heartbeat_attributes = {
  .name = "Heartbeat",
  .priority = (osPriority_t) osPriorityAboveNormal,
  .stack_size = 256 * 4
};
/* Definitions for adcRead */
osThreadId_t adcReadHandle;
const osThreadAttr_t adcRead_attributes = {
  .name = "adcRead",
  .priority = (osPriority_t) osPriorityLow1,
  .stack_size = 256 * 4
};
/* Definitions for DatScreenBlink */
osThreadId_t DatScreenBlinkHandle;
const osThreadAttr_t DatScreenBlink_attributes = {
  .name = "DatScreenBlink",
  .priority = (osPriority_t) osPriorityNormal2,
  .stack_size = 5000 * 4
};
/* Definitions for gpioInputRead */
osThreadId_t gpioInputReadHandle;
const osThreadAttr_t gpioInputRead_attributes = {
  .name = "gpioInputRead",
  .priority = (osPriority_t) osPriorityLow2,
  .stack_size = 256 * 4
};
/* Definitions for navigationTask */
osThreadId_t navigationTaskHandle;
const osThreadAttr_t navigationTask_attributes = {
  .name = "navigationTask",
  .priority = (osPriority_t) osPriorityHigh2,
  .stack_size = 1000 * 4
};
/* Definitions for errorLEDs */
osThreadId_t errorLEDsHandle;
const osThreadAttr_t errorLEDs_attributes = {
  .name = "errorLEDs",
  .priority = (osPriority_t) osPriorityLow5,
  .stack_size = 1024 * 4
};
/* Definitions for zionRead */
osThreadId_t zionReadHandle;
const osThreadAttr_t zionRead_attributes = {
  .name = "zionRead",
  .priority = (osPriority_t) osPriorityHigh1,
  .stack_size = 2000 * 4
};
/* Definitions for bootButtons */
osThreadId_t bootButtonsHandle;
const osThreadAttr_t bootButtons_attributes = {
  .name = "bootButtons",
  .priority = (osPriority_t) osPriorityBelowNormal6,
  .stack_size = 1024 * 4
};
/* Definitions for socUart */
osThreadId_t socUartHandle;
const osThreadAttr_t socUart_attributes = {
  .name = "socUart",
  .priority = (osPriority_t) osPriorityLow7,
  .stack_size = 1024 * 4
};
/* Definitions for debugUart */
osThreadId_t debugUartHandle;
const osThreadAttr_t debugUart_attributes = {
  .name = "debugUart",
  .priority = (osPriority_t) osPriorityLow7,
  .stack_size = 512 * 4
};
/* Definitions for Fault_Events */
osEventFlagsId_t Fault_EventsHandle;
const osEventFlagsAttr_t Fault_Events_attributes = {
  .name = "Fault_Events"
};
/* USER CODE BEGIN PV */
uint16_t adc1_buf[ADC_BUF_LEN];
uint16_t adc2_buf[ADC_BUF_LEN];
uint16_t adc3_buf[ADC_BUF_LEN];

struct adcState adcStates = {0,0,0};
#define ADC_FINISHED			(adcStates.adcBank1Finished && adcStates.adcBank2Finished && adcStates.adcBank3Finished)

uint8_t adcRestart[3];

//SOC I2C Variables
#define SOC_I2C				hi2c2

//SOC UART Variables
#define SOC_UART			huart5
uint8_t soc_Uart_RX_Buf[SOC_UART_BUF_LEN];

//spare Uart Defintions Placed as Huart is only defined later in the file
#define SPARE_UART			huart4
uint8_t spare_Uart_RX_Buf[SPARE_UART_BUF_LEN];

//debug UART variables and Definitions
#define DEBUG_UART			huart7
uint8_t debug_Uart_RX_Buf[DEBUG_UART_BUF_LEN];

//12 gpio inputs to the Dev UI
uint8_t gpioInputBuf[12];
//14 gpio outputs to the Dev UI
uint8_t gpioOutputState[14];
//error LED state Variable
uint8_t errorLEDState[12];

static uint32_t i, j, k;

//zion status variables
struct zion ZION = {0,0, 0, 0, 0, 0, 0, 0, 0, 0, 0, 0, 0, 0};

//boot mode variables
struct bootModeButtons bootButtons = {0,0,0,0,0,0,0,0,0,0};

struct errorLEDs errorLED = {0,0,0,0,0,0,0,0,0,0,0,0,0};

//int commandByte=1;
//int lineByte=1;
//int lineAmount=SCR_H;
//int nopBytesPerLine= 1;
//int dataBytesPerLine=SCR_W/8;
//int finalNOPByte=1;
//uint8_t transmitBuffer[48482];

uint8_t inputButtonSet = NO_BTN_PRESS; //set to a higher value than any other button priority. 5 is the "unused" state
/* USER CODE END PV */

void SystemClock_Config(void);
static void MX_GPIO_Init(void);
static void MX_DMA_Init(void);
static void MX_ADC1_Init(void);
static void MX_ADC2_Init(void);
static void MX_ADC3_Init(void);
static void MX_I2C1_Init(void);
static void MX_I2C2_Init(void);
static void MX_I2C3_Init(void);
static void MX_I2C4_Init(void);
static void MX_RTC_Init(void);
static void MX_SPI4_Init(void);
static void MX_SPI5_Init(void);
static void MX_TIM4_Init(void);
static void MX_TIM5_Init(void);
static void MX_UART4_Init(void);
static void MX_UART5_Init(void);
static void MX_UART7_Init(void);
static void MX_USB_OTG_FS_PCD_Init(void);
void startHeartbeat(void *argument);
void startADCRead(void *argument);
void GetDaScreenBlink(void *argument);
void startGpioInputRead(void *argument);
void startNavigationTask(void *argument);
void startErrorLEDs(void *argument);
void startZionRead(void *argument);
void startBootButtons(void *argument);
void startSocUart(void *argument);
void startDebugUart(void *argument);

/* USER CODE BEGIN PFP */
void debugUartTransmitChar(char *message);
void debugUartTransmitStuff(char *message, int size);
void uartTransmitInt(uint16_t *number, int uart);
uint8_t * readI2CRegister(uint8_t address, uint8_t reg, int bytes, int i2CBank);
void setRGBLED(uint8_t R, uint8_t G, uint8_t B);
void setErrorLED(int led, _Bool change);
void configureLEDDriver();
float* getADCValues();
void uartTransmitFloat(float *number, int uart);
uint8_t *getInputGPIOState(void);
void setOutputGPIOState(int gpio, int state);
void outputGPIOBufInitialization();
void setVoltageMux(int comChannel, int voltageChannel, int clear);
int detectSocVoltageMux();
void winbondSPIDeviceIDRead(SPI_HandleTypeDef hspi, uint8_t* data);
void spareUartTransmitRead(char *message);
uint8_t debugUartParser();
uint8_t * socUartParser();
//void LCD_DrawSomeLinesSingleLine();
//void LCD_DrawSomeLinesBatchLine();
//void LCD_BlackWhite(int color);
/* USER CODE END PFP */

int main(void)
{
  /* USER CODE BEGIN 1 */
 //static _Bool ON = 1;
 //static _Bool OFF = 0;
  HAL_StatusTypeDef Status = HAL_OK;

  /* USER CODE END 1 */

  /* MCU Configuration--------------------------------------------------------*/

  /* Reset of all peripherals, Initializes the Flash interface and the Systick. */
  HAL_Init();

  /* Configure the system clock */
  SystemClock_Config();

  /* Initialize all configured peripherals */
  MX_GPIO_Init();
  MX_DMA_Init();
  MX_ADC1_Init();
  MX_ADC2_Init();
  MX_ADC3_Init();
  MX_I2C1_Init();
  MX_I2C2_Init();
  MX_I2C3_Init();
  MX_I2C4_Init();
  MX_RTC_Init();
  MX_SPI4_Init();
  MX_SPI5_Init();
  MX_TIM4_Init();
  MX_TIM5_Init();
  MX_UART4_Init();
  MX_UART5_Init();
  MX_UART7_Init();
  MX_USB_OTG_FS_PCD_Init();
  /* USER CODE BEGIN 2 */
  //HAL_ADC_ConfigChannel();
  outputGPIOBufInitialization();
  memset(errorLEDState,0,sizeof(errorLEDState));
  HAL_ADC_Start_DMA(&hadc1, (uint32_t*)adc1_buf, ADC_BUF_LEN);
  if (Status != HAL_OK)
  {
  	  DevUI_Error_Handler("ADC1 Failed to start.", Status, 0, 0, true);
  }
  HAL_ADC_Start_DMA(&hadc2, (uint32_t*)adc2_buf, ADC_BUF_LEN);
  if (Status != HAL_OK)
  {
  	  DevUI_Error_Handler("ADC2 Failed to start.", Status, 0, 0, true);
  }
  HAL_ADC_Start_DMA(&hadc3, (uint32_t*)adc3_buf, ADC_BUF_LEN);
  if (Status != HAL_OK)
  {
  	  DevUI_Error_Handler("ADC3 Failed to start.", Status, 0, 0, true);
  }
   int x=1;

   HAL_UART_Receive_DMA(&SPARE_UART, spare_Uart_RX_Buf, sizeof(spare_Uart_RX_Buf));
   HAL_UART_Receive_DMA(&SOC_UART, soc_Uart_RX_Buf, sizeof(soc_Uart_RX_Buf));
   HAL_UART_Receive_DMA(&DEBUG_UART, debug_Uart_RX_Buf, sizeof(debug_Uart_RX_Buf));
//  uint8_t data[5];
//
//  for(x=0;x<5;x++){
//	  data[x]=0xfa+x;
//  }
//  writeDataToSpareEEPROM((uint8_t*)data,SPARE_ADDRESS,0x00,sizeof(data),100);
//  for(int x=0;x<5;x++){
//	  data[x]=0;
//  }
//  readDataFromSpareEEPROM((uint8_t*)data,SPARE_ADDRESS,0x00,sizeof(data),100);
//  data[1]=0;
//  uint8_t spiDataRead[6];
//  memset(data,0x00, sizeof(data));
//  winbondSPIDeviceIDRead(hspi5,(uint8_t*)spiDataRead);
//  //char buf[30];
//  spareUartTransmitRead("Lets see what comes out!");
//  x=0;

  configureLEDDriver();

    setErrorLED(0,ON);
    HAL_Delay(400);
    setErrorLED(1,OFF);
    setErrorLED(8,ON);
    HAL_Delay(400);
    setErrorLED(8,OFF);
    setErrorLED(9,ON);
    HAL_Delay(400);
    setErrorLED(8,ON);
    setErrorLED(9,ON);
    HAL_Delay(400);
    setErrorLED(9,OFF);

    //printf("Welcome to DevUI!\r\n");
    //printf("DevUI SW Version: 0.0.1\r\n");

//    BTN0_ON;
//    HAL_Delay(300);
//    BTN1_ON;
//    HAL_Delay(300);
//    BTN2_ON;
//    HAL_Delay(300);
//    BTN3_ON;
//    HAL_Delay(300);
//    BTN4_ON;
//    HAL_Delay(300);
//    BTN5_ON;
//    HAL_Delay(300);
//    EDL_SW_ON;
//    HAL_Delay(300);
//    EX_SW_ON;
//    HAL_Delay(300);
//    BTN0_OFF;
//    HAL_Delay(300);
//    BTN1_OFF;
//    HAL_Delay(300);
//    BTN2_OFF;
//    HAL_Delay(300);
//    BTN3_OFF;
//    HAL_Delay(300);
//    BTN4_OFF;
//    HAL_Delay(300);
//    BTN5_OFF;
//    HAL_Delay(300);
//    EDL_SW_OFF;
//    HAL_Delay(300);
//    EX_SW_OFF;

  /* USER CODE END 2 */

  /* Init scheduler */
  osKernelInitialize();

  /* Create the thread(s) */
  /* creation of Heartbeat */
  HeartbeatHandle = osThreadNew(startHeartbeat, NULL, &Heartbeat_attributes);

  /* creation of adcRead */
  adcReadHandle = osThreadNew(startADCRead, NULL, &adcRead_attributes);

  /* creation of DatScreenBlink */
  DatScreenBlinkHandle = osThreadNew(GetDaScreenBlink, NULL, &DatScreenBlink_attributes);

  /* creation of gpioInputRead */
  gpioInputReadHandle = osThreadNew(startGpioInputRead, NULL, &gpioInputRead_attributes);

  /* creation of navigationTask */
  navigationTaskHandle = osThreadNew(startNavigationTask, NULL, &navigationTask_attributes);

  /* creation of errorLEDs */
  errorLEDsHandle = osThreadNew(startErrorLEDs, NULL, &errorLEDs_attributes);

  /* creation of zionRead */
  zionReadHandle = osThreadNew(startZionRead, NULL, &zionRead_attributes);

  /* creation of bootButtons */
  bootButtonsHandle = osThreadNew(startBootButtons, NULL, &bootButtons_attributes);

  /* creation of socUart */
  socUartHandle = osThreadNew(startSocUart, NULL, &socUart_attributes);

  /* creation of debugUart */
  debugUartHandle = osThreadNew(startDebugUart, NULL, &debugUart_attributes);

  /* Create the event(s) */
  /* creation of Fault_Events */
  Fault_EventsHandle = osEventFlagsNew(&Fault_Events_attributes);

  /* USER CODE BEGIN RTOS_EVENTS */
  /* Fault Events Bit map
	   bit 0: Zion Fault
	   bit 1: vsysPMI Fault
	   bit 2: fault 3
	   bit 3: fault 4
	   bit 4: fault 5
	   bit 5: fault 6
	   bit 6: fault 7
	   bit 7: fault 8
	   bit 8: fault 9
	   bit 9: standard boot
	   bit 10: edl boot
	   bit 11: uefi boot
   */
  if (Fault_EventsHandle == NULL)
  {
	  // Event flags object not created, handle failure.
	  DevUI_Error_Handler("Faults Event Flag could not be created.\r\n",HAL_ERROR,0,0,true);
  }
  else
  {
	  // clear all event flags
	  osEventFlagsClear(Fault_EventsHandle, 0xFFFF);
  }
  /* add events, ... */
  /* USER CODE END RTOS_EVENTS */

  /* Start scheduler */
  osKernelStart();

  /* We should never get here as control is now taken by the scheduler */
  /* Infinite loop */
  /* USER CODE BEGIN WHILE */

  while (1)
  {
	  HAL_Delay(1000);
	  if (!x) {
		  HAL_GPIO_WritePin(GPIOI,MCU_HEARTBEAT_Pin,GPIO_PIN_SET);
		  x=1;

		  //uartTransmitChar("hello\r\n",7);
		  HAL_GPIO_WritePin(LCD_SS_GPIO_Port,LCD_SS_Pin,GPIO_PIN_SET);
		  //HAL_SPI_Transmit(&hspi4, (uint16_t *)&LCD_Blink_White, 1, 100);
		  HAL_GPIO_WritePin(LCD_SS_GPIO_Port,LCD_SS_Pin,GPIO_PIN_RESET);
	  }
	  else{
		  HAL_GPIO_WritePin(GPIOI,MCU_HEARTBEAT_Pin,GPIO_PIN_RESET);
		  x=0;
		  //uartTransmitChar("here\r\n",7);
		  HAL_GPIO_WritePin(LCD_SS_GPIO_Port,LCD_SS_Pin,GPIO_PIN_SET);
		  //HAL_SPI_Transmit(&hspi4, (uint16_t *)&LCD_Blink_Black, 1, 100);
		  HAL_GPIO_WritePin(LCD_SS_GPIO_Port,LCD_SS_Pin,GPIO_PIN_RESET);
	  }
    /* USER CODE END WHILE */

  }
}

void SystemClock_Config(void)
{
  RCC_OscInitTypeDef RCC_OscInitStruct = {0};
  RCC_ClkInitTypeDef RCC_ClkInitStruct = {0};
  RCC_PeriphCLKInitTypeDef PeriphClkInitStruct = {0};

  /** Configure LSE Drive Capability
  */
  HAL_PWR_EnableBkUpAccess();
  __HAL_RCC_LSEDRIVE_CONFIG(RCC_LSEDRIVE_LOW);
  /** Configure the main internal regulator output voltage
  */
  __HAL_RCC_PWR_CLK_ENABLE();
  __HAL_PWR_VOLTAGESCALING_CONFIG(PWR_REGULATOR_VOLTAGE_SCALE3);
  /** Initializes the RCC Oscillators according to the specified parameters
  * in the RCC_OscInitTypeDef structure.
  */
  RCC_OscInitStruct.OscillatorType = RCC_OSCILLATORTYPE_HSE|RCC_OSCILLATORTYPE_LSE;
  RCC_OscInitStruct.HSEState = RCC_HSE_ON;
  RCC_OscInitStruct.LSEState = RCC_LSE_ON;
  RCC_OscInitStruct.PLL.PLLState = RCC_PLL_ON;
  RCC_OscInitStruct.PLL.PLLSource = RCC_PLLSOURCE_HSE;
  RCC_OscInitStruct.PLL.PLLM = 15;
  RCC_OscInitStruct.PLL.PLLN = 144;
  RCC_OscInitStruct.PLL.PLLP = RCC_PLLP_DIV2;
  RCC_OscInitStruct.PLL.PLLQ = 5;
  if (HAL_RCC_OscConfig(&RCC_OscInitStruct) != HAL_OK)
  {
    Error_Handler();
  }
  /** Initializes the CPU, AHB and APB buses clocks
  */
  RCC_ClkInitStruct.ClockType = RCC_CLOCKTYPE_HCLK|RCC_CLOCKTYPE_SYSCLK
                              |RCC_CLOCKTYPE_PCLK1|RCC_CLOCKTYPE_PCLK2;
  RCC_ClkInitStruct.SYSCLKSource = RCC_SYSCLKSOURCE_PLLCLK;
  RCC_ClkInitStruct.AHBCLKDivider = RCC_SYSCLK_DIV1;
  RCC_ClkInitStruct.APB1CLKDivider = RCC_HCLK_DIV4;
  RCC_ClkInitStruct.APB2CLKDivider = RCC_HCLK_DIV2;

  if (HAL_RCC_ClockConfig(&RCC_ClkInitStruct, FLASH_LATENCY_3) != HAL_OK)
  {
    Error_Handler();
  }
  PeriphClkInitStruct.PeriphClockSelection = RCC_PERIPHCLK_RTC|RCC_PERIPHCLK_UART4
                              |RCC_PERIPHCLK_UART5|RCC_PERIPHCLK_UART7
                              |RCC_PERIPHCLK_I2C1|RCC_PERIPHCLK_I2C2
                              |RCC_PERIPHCLK_I2C3|RCC_PERIPHCLK_I2C4
                              |RCC_PERIPHCLK_CLK48;
  PeriphClkInitStruct.RTCClockSelection = RCC_RTCCLKSOURCE_LSE;
  PeriphClkInitStruct.Uart4ClockSelection = RCC_UART4CLKSOURCE_PCLK1;
  PeriphClkInitStruct.Uart5ClockSelection = RCC_UART5CLKSOURCE_PCLK1;
  PeriphClkInitStruct.Uart7ClockSelection = RCC_UART7CLKSOURCE_PCLK1;
  PeriphClkInitStruct.I2c1ClockSelection = RCC_I2C1CLKSOURCE_PCLK1;
  PeriphClkInitStruct.I2c2ClockSelection = RCC_I2C2CLKSOURCE_PCLK1;
  PeriphClkInitStruct.I2c3ClockSelection = RCC_I2C3CLKSOURCE_PCLK1;
  PeriphClkInitStruct.I2c4ClockSelection = RCC_I2C4CLKSOURCE_PCLK1;
  PeriphClkInitStruct.Clk48ClockSelection = RCC_CLK48SOURCE_PLL;
  if (HAL_RCCEx_PeriphCLKConfig(&PeriphClkInitStruct) != HAL_OK)
  {
    Error_Handler();
  }
}

static void MX_ADC1_Init(void)
{

  ADC_ChannelConfTypeDef sConfig = {0};

  /** Configure the global features of the ADC (Clock, Resolution, Data Alignment and number of conversion)
  */
  hadc1.Instance = ADC1;
  hadc1.Init.ClockPrescaler = ADC_CLOCK_SYNC_PCLK_DIV4;
  hadc1.Init.Resolution = ADC_RESOLUTION_12B;
  hadc1.Init.ScanConvMode = ADC_SCAN_ENABLE;
  hadc1.Init.ContinuousConvMode = ENABLE;
  hadc1.Init.DiscontinuousConvMode = DISABLE;
  hadc1.Init.ExternalTrigConvEdge = ADC_EXTERNALTRIGCONVEDGE_NONE;
  hadc1.Init.ExternalTrigConv = ADC_SOFTWARE_START;
  hadc1.Init.DataAlign = ADC_DATAALIGN_RIGHT;
  hadc1.Init.NbrOfConversion = 11;
  hadc1.Init.DMAContinuousRequests = ENABLE;
  hadc1.Init.EOCSelection = ADC_EOC_SINGLE_CONV;
  if (HAL_ADC_Init(&hadc1) != HAL_OK)
  {
    Error_Handler();
  }
  /** Configure for the selected ADC regular channel its corresponding rank in the sequencer and its sample time.
  */
  sConfig.Channel = ADC_CHANNEL_3;
  sConfig.Rank = ADC_REGULAR_RANK_1;
  sConfig.SamplingTime = ADC_SAMPLETIME_480CYCLES;
  if (HAL_ADC_ConfigChannel(&hadc1, &sConfig) != HAL_OK)
  {
    Error_Handler();
  }
  /** Configure for the selected ADC regular channel its corresponding rank in the sequencer and its sample time.
  */
  sConfig.Channel = ADC_CHANNEL_4;
  sConfig.Rank = ADC_REGULAR_RANK_2;
  if (HAL_ADC_ConfigChannel(&hadc1, &sConfig) != HAL_OK)
  {
    Error_Handler();
  }
  /** Configure for the selected ADC regular channel its corresponding rank in the sequencer and its sample time.
  */
  sConfig.Channel = ADC_CHANNEL_5;
  sConfig.Rank = ADC_REGULAR_RANK_3;
  if (HAL_ADC_ConfigChannel(&hadc1, &sConfig) != HAL_OK)
  {
    Error_Handler();
  }
  /** Configure for the selected ADC regular channel its corresponding rank in the sequencer and its sample time.
  */
  sConfig.Channel = ADC_CHANNEL_6;
  sConfig.Rank = ADC_REGULAR_RANK_4;
  if (HAL_ADC_ConfigChannel(&hadc1, &sConfig) != HAL_OK)
  {
    Error_Handler();
  }
  /** Configure for the selected ADC regular channel its corresponding rank in the sequencer and its sample time.
  */
  sConfig.Channel = ADC_CHANNEL_7;
  sConfig.Rank = ADC_REGULAR_RANK_5;
  if (HAL_ADC_ConfigChannel(&hadc1, &sConfig) != HAL_OK)
  {
    Error_Handler();
  }
  /** Configure for the selected ADC regular channel its corresponding rank in the sequencer and its sample time.
  */
  sConfig.Channel = ADC_CHANNEL_8;
  sConfig.Rank = ADC_REGULAR_RANK_6;
  if (HAL_ADC_ConfigChannel(&hadc1, &sConfig) != HAL_OK)
  {
    Error_Handler();
  }
  /** Configure for the selected ADC regular channel its corresponding rank in the sequencer and its sample time.
  */
  sConfig.Channel = ADC_CHANNEL_9;
  sConfig.Rank = ADC_REGULAR_RANK_7;
  if (HAL_ADC_ConfigChannel(&hadc1, &sConfig) != HAL_OK)
  {
    Error_Handler();
  }
  /** Configure for the selected ADC regular channel its corresponding rank in the sequencer and its sample time.
  */
  sConfig.Channel = ADC_CHANNEL_10;
  sConfig.Rank = ADC_REGULAR_RANK_8;
  if (HAL_ADC_ConfigChannel(&hadc1, &sConfig) != HAL_OK)
  {
    Error_Handler();
  }
  /** Configure for the selected ADC regular channel its corresponding rank in the sequencer and its sample time.
  */
  sConfig.Channel = ADC_CHANNEL_11;
  sConfig.Rank = ADC_REGULAR_RANK_9;
  if (HAL_ADC_ConfigChannel(&hadc1, &sConfig) != HAL_OK)
  {
    Error_Handler();
  }
  /** Configure for the selected ADC regular channel its corresponding rank in the sequencer and its sample time.
  */
  sConfig.Channel = ADC_CHANNEL_12;
  sConfig.Rank = ADC_REGULAR_RANK_10;
  if (HAL_ADC_ConfigChannel(&hadc1, &sConfig) != HAL_OK)
  {
    Error_Handler();
  }
  /** Configure for the selected ADC regular channel its corresponding rank in the sequencer and its sample time.
  */
  sConfig.Channel = ADC_CHANNEL_13;
  sConfig.Rank = ADC_REGULAR_RANK_11;
  if (HAL_ADC_ConfigChannel(&hadc1, &sConfig) != HAL_OK)
  {
    Error_Handler();
  }

}

static void MX_ADC2_Init(void)
{

  ADC_ChannelConfTypeDef sConfig = {0};

  /** Configure the global features of the ADC (Clock, Resolution, Data Alignment and number of conversion)
  */
  hadc2.Instance = ADC2;
  hadc2.Init.ClockPrescaler = ADC_CLOCK_SYNC_PCLK_DIV4;
  hadc2.Init.Resolution = ADC_RESOLUTION_12B;
  hadc2.Init.ScanConvMode = ADC_SCAN_ENABLE;
  hadc2.Init.ContinuousConvMode = ENABLE;
  hadc2.Init.DiscontinuousConvMode = DISABLE;
  hadc2.Init.ExternalTrigConvEdge = ADC_EXTERNALTRIGCONVEDGE_NONE;
  hadc2.Init.ExternalTrigConv = ADC_SOFTWARE_START;
  hadc2.Init.DataAlign = ADC_DATAALIGN_RIGHT;
  hadc2.Init.NbrOfConversion = 4;
  hadc2.Init.DMAContinuousRequests = ENABLE;
  hadc2.Init.EOCSelection = ADC_EOC_SINGLE_CONV;
  if (HAL_ADC_Init(&hadc2) != HAL_OK)
  {
    Error_Handler();
  }
  /** Configure for the selected ADC regular channel its corresponding rank in the sequencer and its sample time.
  */
  sConfig.Channel = ADC_CHANNEL_0;
  sConfig.Rank = ADC_REGULAR_RANK_1;
  sConfig.SamplingTime = ADC_SAMPLETIME_480CYCLES;
  if (HAL_ADC_ConfigChannel(&hadc2, &sConfig) != HAL_OK)
  {
    Error_Handler();
  }
  /** Configure for the selected ADC regular channel its corresponding rank in the sequencer and its sample time.
  */
  sConfig.Channel = ADC_CHANNEL_1;
  sConfig.Rank = ADC_REGULAR_RANK_2;
  if (HAL_ADC_ConfigChannel(&hadc2, &sConfig) != HAL_OK)
  {
    Error_Handler();
  }
  /** Configure for the selected ADC regular channel its corresponding rank in the sequencer and its sample time.
  */
  sConfig.Channel = ADC_CHANNEL_14;
  sConfig.Rank = ADC_REGULAR_RANK_3;
  if (HAL_ADC_ConfigChannel(&hadc2, &sConfig) != HAL_OK)
  {
    Error_Handler();
  }
  /** Configure for the selected ADC regular channel its corresponding rank in the sequencer and its sample time.
  */
  sConfig.Channel = ADC_CHANNEL_15;
  sConfig.Rank = ADC_REGULAR_RANK_4;
  if (HAL_ADC_ConfigChannel(&hadc2, &sConfig) != HAL_OK)
  {
    Error_Handler();
  }

}

static void MX_ADC3_Init(void)
{

  ADC_ChannelConfTypeDef sConfig = {0};

  /** Configure the global features of the ADC (Clock, Resolution, Data Alignment and number of conversion)
  */
  hadc3.Instance = ADC3;
  hadc3.Init.ClockPrescaler = ADC_CLOCK_SYNC_PCLK_DIV4;
  hadc3.Init.Resolution = ADC_RESOLUTION_12B;
  hadc3.Init.ScanConvMode = ADC_SCAN_ENABLE;
  hadc3.Init.ContinuousConvMode = ENABLE;
  hadc3.Init.DiscontinuousConvMode = DISABLE;
  hadc3.Init.ExternalTrigConvEdge = ADC_EXTERNALTRIGCONVEDGE_NONE;
  hadc3.Init.ExternalTrigConv = ADC_SOFTWARE_START;
  hadc3.Init.DataAlign = ADC_DATAALIGN_RIGHT;
  hadc3.Init.NbrOfConversion = 6;
  hadc3.Init.DMAContinuousRequests = ENABLE;
  hadc3.Init.EOCSelection = ADC_EOC_SINGLE_CONV;
  if (HAL_ADC_Init(&hadc3) != HAL_OK)
  {
    Error_Handler();
  }
  /** Configure for the selected ADC regular channel its corresponding rank in the sequencer and its sample time.
  */
  sConfig.Channel = ADC_CHANNEL_2;
  sConfig.Rank = ADC_REGULAR_RANK_1;
  sConfig.SamplingTime = ADC_SAMPLETIME_480CYCLES;
  if (HAL_ADC_ConfigChannel(&hadc3, &sConfig) != HAL_OK)
  {
    Error_Handler();
  }
  /** Configure for the selected ADC regular channel its corresponding rank in the sequencer and its sample time.
  */
  sConfig.Channel = ADC_CHANNEL_4;
  sConfig.Rank = ADC_REGULAR_RANK_2;
  if (HAL_ADC_ConfigChannel(&hadc3, &sConfig) != HAL_OK)
  {
    Error_Handler();
  }
  /** Configure for the selected ADC regular channel its corresponding rank in the sequencer and its sample time.
  */
  sConfig.Channel = ADC_CHANNEL_5;
  sConfig.Rank = ADC_REGULAR_RANK_3;
  if (HAL_ADC_ConfigChannel(&hadc3, &sConfig) != HAL_OK)
  {
    Error_Handler();
  }
  /** Configure for the selected ADC regular channel its corresponding rank in the sequencer and its sample time.
  */
  sConfig.Channel = ADC_CHANNEL_6;
  sConfig.Rank = ADC_REGULAR_RANK_4;
  if (HAL_ADC_ConfigChannel(&hadc3, &sConfig) != HAL_OK)
  {
    Error_Handler();
  }
  /** Configure for the selected ADC regular channel its corresponding rank in the sequencer and its sample time.
  */
  sConfig.Channel = ADC_CHANNEL_7;
  sConfig.Rank = ADC_REGULAR_RANK_5;
  if (HAL_ADC_ConfigChannel(&hadc3, &sConfig) != HAL_OK)
  {
    Error_Handler();
  }
  /** Configure for the selected ADC regular channel its corresponding rank in the sequencer and its sample time.
  */
  sConfig.Channel = ADC_CHANNEL_8;
  sConfig.Rank = ADC_REGULAR_RANK_6;
  if (HAL_ADC_ConfigChannel(&hadc3, &sConfig) != HAL_OK)
  {
    Error_Handler();
  }

}

static void MX_I2C1_Init(void)
{

  hi2c1.Instance = I2C1;
  hi2c1.Init.Timing = 0x007074AF;
  hi2c1.Init.OwnAddress1 = 0;
  hi2c1.Init.AddressingMode = I2C_ADDRESSINGMODE_7BIT;
  hi2c1.Init.DualAddressMode = I2C_DUALADDRESS_DISABLE;
  hi2c1.Init.OwnAddress2 = 0;
  hi2c1.Init.OwnAddress2Masks = I2C_OA2_NOMASK;
  hi2c1.Init.GeneralCallMode = I2C_GENERALCALL_DISABLE;
  hi2c1.Init.NoStretchMode = I2C_NOSTRETCH_DISABLE;
  if (HAL_I2C_Init(&hi2c1) != HAL_OK)
  {
    Error_Handler();
  }
  /** Configure Analogue filter
  */
  if (HAL_I2CEx_ConfigAnalogFilter(&hi2c1, I2C_ANALOGFILTER_ENABLE) != HAL_OK)
  {
    Error_Handler();
  }
  /** Configure Digital filter
  */
  if (HAL_I2CEx_ConfigDigitalFilter(&hi2c1, 0) != HAL_OK)
  {
    Error_Handler();
  }

}

static void MX_I2C2_Init(void)
{

  hi2c2.Instance = I2C2;
  hi2c2.Init.Timing = 0x007074AF;
  hi2c2.Init.OwnAddress1 = 0;
  hi2c2.Init.AddressingMode = I2C_ADDRESSINGMODE_7BIT;
  hi2c2.Init.DualAddressMode = I2C_DUALADDRESS_DISABLE;
  hi2c2.Init.OwnAddress2 = 0;
  hi2c2.Init.OwnAddress2Masks = I2C_OA2_NOMASK;
  hi2c2.Init.GeneralCallMode = I2C_GENERALCALL_DISABLE;
  hi2c2.Init.NoStretchMode = I2C_NOSTRETCH_DISABLE;
  if (HAL_I2C_Init(&hi2c2) != HAL_OK)
  {
    Error_Handler();
  }
  /** Configure Analogue filter
  */
  if (HAL_I2CEx_ConfigAnalogFilter(&hi2c2, I2C_ANALOGFILTER_ENABLE) != HAL_OK)
  {
    Error_Handler();
  }
  /** Configure Digital filter
  */
  if (HAL_I2CEx_ConfigDigitalFilter(&hi2c2, 0) != HAL_OK)
  {
    Error_Handler();
  }

}

static void MX_I2C3_Init(void)
{

  hi2c3.Instance = I2C3;
  hi2c3.Init.Timing = 0x100029FE;
  hi2c3.Init.OwnAddress1 = 152;
  hi2c3.Init.AddressingMode = I2C_ADDRESSINGMODE_7BIT;
  hi2c3.Init.DualAddressMode = I2C_DUALADDRESS_DISABLE;
  hi2c3.Init.OwnAddress2 = 0;
  hi2c3.Init.OwnAddress2Masks = I2C_OA2_NOMASK;
  hi2c3.Init.GeneralCallMode = I2C_GENERALCALL_DISABLE;
  hi2c3.Init.NoStretchMode = I2C_NOSTRETCH_DISABLE;
  if (HAL_I2C_Init(&hi2c3) != HAL_OK)
  {
    Error_Handler();
  }
  /** Configure Analogue filter
  */
  if (HAL_I2CEx_ConfigAnalogFilter(&hi2c3, I2C_ANALOGFILTER_ENABLE) != HAL_OK)
  {
    Error_Handler();
  }
  /** Configure Digital filter
  */
  if (HAL_I2CEx_ConfigDigitalFilter(&hi2c3, 0) != HAL_OK)
  {
    Error_Handler();
  }
  /** I2C Enable Fast Mode Plus
  */
  HAL_I2CEx_EnableFastModePlus(I2C_FASTMODEPLUS_I2C3);

}

static void MX_I2C4_Init(void)
{

  hi2c4.Instance = I2C4;
  hi2c4.Init.Timing = 0x007074AF;
  hi2c4.Init.OwnAddress1 = 0;
  hi2c4.Init.AddressingMode = I2C_ADDRESSINGMODE_7BIT;
  hi2c4.Init.DualAddressMode = I2C_DUALADDRESS_DISABLE;
  hi2c4.Init.OwnAddress2 = 0;
  hi2c4.Init.OwnAddress2Masks = I2C_OA2_NOMASK;
  hi2c4.Init.GeneralCallMode = I2C_GENERALCALL_DISABLE;
  hi2c4.Init.NoStretchMode = I2C_NOSTRETCH_DISABLE;
  if (HAL_I2C_Init(&hi2c4) != HAL_OK)
  {
    Error_Handler();
  }
  /** Configure Analogue filter
  */
  if (HAL_I2CEx_ConfigAnalogFilter(&hi2c4, I2C_ANALOGFILTER_ENABLE) != HAL_OK)
  {
    Error_Handler();
  }
  /** Configure Digital filter
  */
  if (HAL_I2CEx_ConfigDigitalFilter(&hi2c4, 0) != HAL_OK)
  {
    Error_Handler();
  }

}

static void MX_RTC_Init(void)
{

  /** Initialize RTC Only
  */
  hrtc.Instance = RTC;
  hrtc.Init.HourFormat = RTC_HOURFORMAT_24;
  hrtc.Init.AsynchPrediv = 127;
  hrtc.Init.SynchPrediv = 255;
  hrtc.Init.OutPut = RTC_OUTPUT_DISABLE;
  hrtc.Init.OutPutPolarity = RTC_OUTPUT_POLARITY_HIGH;
  hrtc.Init.OutPutType = RTC_OUTPUT_TYPE_OPENDRAIN;
  if (HAL_RTC_Init(&hrtc) != HAL_OK)
  {
    Error_Handler();
  }

}

static void MX_SPI4_Init(void)
{

  /* SPI4 parameter configuration*/
  hspi4.Instance = SPI4;
  hspi4.Init.Mode = SPI_MODE_MASTER;
  hspi4.Init.Direction = SPI_DIRECTION_2LINES;
  hspi4.Init.DataSize = SPI_DATASIZE_8BIT;
  hspi4.Init.CLKPolarity = SPI_POLARITY_LOW;
  hspi4.Init.CLKPhase = SPI_PHASE_1EDGE;
  hspi4.Init.NSS = SPI_NSS_SOFT;
  hspi4.Init.BaudRatePrescaler = SPI_BAUDRATEPRESCALER_8;
  hspi4.Init.FirstBit = SPI_FIRSTBIT_MSB;
  hspi4.Init.TIMode = SPI_TIMODE_DISABLE;
  hspi4.Init.CRCCalculation = SPI_CRCCALCULATION_DISABLE;
  hspi4.Init.CRCPolynomial = 7;
  hspi4.Init.CRCLength = SPI_CRC_LENGTH_DATASIZE;
  hspi4.Init.NSSPMode = SPI_NSS_PULSE_DISABLE;
  if (HAL_SPI_Init(&hspi4) != HAL_OK)
  {
    Error_Handler();
  }

}

static void MX_SPI5_Init(void)
{

  /* SPI5 parameter configuration*/
  hspi5.Instance = SPI5;
  hspi5.Init.Mode = SPI_MODE_MASTER;
  hspi5.Init.Direction = SPI_DIRECTION_2LINES;
  hspi5.Init.DataSize = SPI_DATASIZE_8BIT;
  hspi5.Init.CLKPolarity = SPI_POLARITY_LOW;
  hspi5.Init.CLKPhase = SPI_PHASE_1EDGE;
  hspi5.Init.NSS = SPI_NSS_HARD_OUTPUT;
  hspi5.Init.BaudRatePrescaler = SPI_BAUDRATEPRESCALER_16;
  hspi5.Init.FirstBit = SPI_FIRSTBIT_MSB;
  hspi5.Init.TIMode = SPI_TIMODE_DISABLE;
  hspi5.Init.CRCCalculation = SPI_CRCCALCULATION_DISABLE;
  hspi5.Init.CRCPolynomial = 7;
  hspi5.Init.CRCLength = SPI_CRC_LENGTH_DATASIZE;
  hspi5.Init.NSSPMode = SPI_NSS_PULSE_DISABLE;
  if (HAL_SPI_Init(&hspi5) != HAL_OK)
  {
    Error_Handler();
  }

}

static void MX_TIM4_Init(void)
{

  TIM_ClockConfigTypeDef sClockSourceConfig = {0};
  TIM_MasterConfigTypeDef sMasterConfig = {0};
  TIM_OC_InitTypeDef sConfigOC = {0};

  htim4.Instance = TIM4;
  htim4.Init.Prescaler = 0;
  htim4.Init.CounterMode = TIM_COUNTERMODE_UP;
  htim4.Init.Period = 65535;
  htim4.Init.ClockDivision = TIM_CLOCKDIVISION_DIV1;
  htim4.Init.AutoReloadPreload = TIM_AUTORELOAD_PRELOAD_DISABLE;
  if (HAL_TIM_Base_Init(&htim4) != HAL_OK)
  {
    Error_Handler();
  }
  sClockSourceConfig.ClockSource = TIM_CLOCKSOURCE_INTERNAL;
  if (HAL_TIM_ConfigClockSource(&htim4, &sClockSourceConfig) != HAL_OK)
  {
    Error_Handler();
  }
  if (HAL_TIM_PWM_Init(&htim4) != HAL_OK)
  {
    Error_Handler();
  }
  sMasterConfig.MasterOutputTrigger = TIM_TRGO_RESET;
  sMasterConfig.MasterSlaveMode = TIM_MASTERSLAVEMODE_DISABLE;
  if (HAL_TIMEx_MasterConfigSynchronization(&htim4, &sMasterConfig) != HAL_OK)
  {
    Error_Handler();
  }
  sConfigOC.OCMode = TIM_OCMODE_PWM1;
  sConfigOC.Pulse = 0;
  sConfigOC.OCPolarity = TIM_OCPOLARITY_HIGH;
  sConfigOC.OCFastMode = TIM_OCFAST_DISABLE;
  if (HAL_TIM_PWM_ConfigChannel(&htim4, &sConfigOC, TIM_CHANNEL_1) != HAL_OK)
  {
    Error_Handler();
  }
  HAL_TIM_MspPostInit(&htim4);

}

static void MX_TIM5_Init(void)
{

  TIM_ClockConfigTypeDef sClockSourceConfig = {0};
  TIM_MasterConfigTypeDef sMasterConfig = {0};
  TIM_OC_InitTypeDef sConfigOC = {0};

  htim5.Instance = TIM5;
  htim5.Init.Prescaler = 0;
  htim5.Init.CounterMode = TIM_COUNTERMODE_UP;
  htim5.Init.Period = 4294967295;
  htim5.Init.ClockDivision = TIM_CLOCKDIVISION_DIV1;
  htim5.Init.AutoReloadPreload = TIM_AUTORELOAD_PRELOAD_DISABLE;
  if (HAL_TIM_Base_Init(&htim5) != HAL_OK)
  {
    Error_Handler();
  }
  sClockSourceConfig.ClockSource = TIM_CLOCKSOURCE_INTERNAL;
  if (HAL_TIM_ConfigClockSource(&htim5, &sClockSourceConfig) != HAL_OK)
  {
    Error_Handler();
  }
  if (HAL_TIM_PWM_Init(&htim5) != HAL_OK)
  {
    Error_Handler();
  }
  sMasterConfig.MasterOutputTrigger = TIM_TRGO_RESET;
  sMasterConfig.MasterSlaveMode = TIM_MASTERSLAVEMODE_DISABLE;
  if (HAL_TIMEx_MasterConfigSynchronization(&htim5, &sMasterConfig) != HAL_OK)
  {
    Error_Handler();
  }
  sConfigOC.OCMode = TIM_OCMODE_PWM1;
  sConfigOC.Pulse = 0;
  sConfigOC.OCPolarity = TIM_OCPOLARITY_HIGH;
  sConfigOC.OCFastMode = TIM_OCFAST_DISABLE;
  if (HAL_TIM_PWM_ConfigChannel(&htim5, &sConfigOC, TIM_CHANNEL_1) != HAL_OK)
  {
    Error_Handler();
  }
  if (HAL_TIM_PWM_ConfigChannel(&htim5, &sConfigOC, TIM_CHANNEL_2) != HAL_OK)
  {
    Error_Handler();
  }
  HAL_TIM_MspPostInit(&htim5);

}

static void MX_UART4_Init(void)
{

  huart4.Instance = UART4;
  huart4.Init.BaudRate = 115200;
  huart4.Init.WordLength = UART_WORDLENGTH_8B;
  huart4.Init.StopBits = UART_STOPBITS_1;
  huart4.Init.Parity = UART_PARITY_NONE;
  huart4.Init.Mode = UART_MODE_TX_RX;
  huart4.Init.HwFlowCtl = UART_HWCONTROL_NONE;
  huart4.Init.OverSampling = UART_OVERSAMPLING_16;
  huart4.Init.OneBitSampling = UART_ONE_BIT_SAMPLE_DISABLE;
  huart4.AdvancedInit.AdvFeatureInit = UART_ADVFEATURE_NO_INIT;
  if (HAL_UART_Init(&huart4) != HAL_OK)
  {
    Error_Handler();
  }

}

static void MX_UART5_Init(void)
{

  huart5.Instance = UART5;
  huart5.Init.BaudRate = 115200;
  huart5.Init.WordLength = UART_WORDLENGTH_8B;
  huart5.Init.StopBits = UART_STOPBITS_1;
  huart5.Init.Parity = UART_PARITY_NONE;
  huart5.Init.Mode = UART_MODE_TX_RX;
  huart5.Init.HwFlowCtl = UART_HWCONTROL_NONE;
  huart5.Init.OverSampling = UART_OVERSAMPLING_16;
  huart5.Init.OneBitSampling = UART_ONE_BIT_SAMPLE_DISABLE;
  huart5.AdvancedInit.AdvFeatureInit = UART_ADVFEATURE_NO_INIT;
  if (HAL_UART_Init(&huart5) != HAL_OK)
  {
    Error_Handler();
  }

}

static void MX_UART7_Init(void)
{

  huart7.Instance = UART7;
  huart7.Init.BaudRate = 115200;
  huart7.Init.WordLength = UART_WORDLENGTH_8B;
  huart7.Init.StopBits = UART_STOPBITS_1;
  huart7.Init.Parity = UART_PARITY_NONE;
  huart7.Init.Mode = UART_MODE_TX_RX;
  huart7.Init.HwFlowCtl = UART_HWCONTROL_RTS_CTS;
  huart7.Init.OverSampling = UART_OVERSAMPLING_16;
  huart7.Init.OneBitSampling = UART_ONE_BIT_SAMPLE_DISABLE;
  huart7.AdvancedInit.AdvFeatureInit = UART_ADVFEATURE_NO_INIT;
  if (HAL_UART_Init(&huart7) != HAL_OK)
  {
    Error_Handler();
  }

}

static void MX_USB_OTG_FS_PCD_Init(void)
{

  hpcd_USB_OTG_FS.Instance = USB_OTG_FS;
  hpcd_USB_OTG_FS.Init.dev_endpoints = 6;
  hpcd_USB_OTG_FS.Init.speed = PCD_SPEED_FULL;
  hpcd_USB_OTG_FS.Init.dma_enable = DISABLE;
  hpcd_USB_OTG_FS.Init.phy_itface = PCD_PHY_EMBEDDED;
  hpcd_USB_OTG_FS.Init.Sof_enable = DISABLE;
  hpcd_USB_OTG_FS.Init.low_power_enable = DISABLE;
  hpcd_USB_OTG_FS.Init.lpm_enable = DISABLE;
  hpcd_USB_OTG_FS.Init.vbus_sensing_enable = DISABLE;
  hpcd_USB_OTG_FS.Init.use_dedicated_ep1 = DISABLE;
  if (HAL_PCD_Init(&hpcd_USB_OTG_FS) != HAL_OK)
  {
    Error_Handler();
  }

}

static void MX_DMA_Init(void)
{

  /* DMA controller clock enable */
  __HAL_RCC_DMA2_CLK_ENABLE();
  __HAL_RCC_DMA1_CLK_ENABLE();

  /* DMA interrupt init */
  /* DMA1_Stream0_IRQn interrupt configuration */
  HAL_NVIC_SetPriority(DMA1_Stream0_IRQn, 5, 0);
  HAL_NVIC_EnableIRQ(DMA1_Stream0_IRQn);
  /* DMA1_Stream2_IRQn interrupt configuration */
  HAL_NVIC_SetPriority(DMA1_Stream2_IRQn, 5, 0);
  HAL_NVIC_EnableIRQ(DMA1_Stream2_IRQn);
  /* DMA1_Stream3_IRQn interrupt configuration */
  HAL_NVIC_SetPriority(DMA1_Stream3_IRQn, 5, 0);
  HAL_NVIC_EnableIRQ(DMA1_Stream3_IRQn);
  /* DMA2_Stream0_IRQn interrupt configuration */
  HAL_NVIC_SetPriority(DMA2_Stream0_IRQn, 5, 0);
  HAL_NVIC_EnableIRQ(DMA2_Stream0_IRQn);
  /* DMA2_Stream1_IRQn interrupt configuration */
  HAL_NVIC_SetPriority(DMA2_Stream1_IRQn, 5, 0);
  HAL_NVIC_EnableIRQ(DMA2_Stream1_IRQn);
  /* DMA2_Stream2_IRQn interrupt configuration */
  HAL_NVIC_SetPriority(DMA2_Stream2_IRQn, 5, 0);
  HAL_NVIC_EnableIRQ(DMA2_Stream2_IRQn);

}

static void MX_GPIO_Init(void)
{
  GPIO_InitTypeDef GPIO_InitStruct = {0};

  /* GPIO Ports Clock Enable */
  __HAL_RCC_GPIOE_CLK_ENABLE();
  __HAL_RCC_GPIOG_CLK_ENABLE();
  __HAL_RCC_GPIOB_CLK_ENABLE();
  __HAL_RCC_GPIOC_CLK_ENABLE();
  __HAL_RCC_GPIOA_CLK_ENABLE();
  __HAL_RCC_GPIOI_CLK_ENABLE();
  __HAL_RCC_GPIOK_CLK_ENABLE();
  __HAL_RCC_GPIOF_CLK_ENABLE();
  __HAL_RCC_GPIOD_CLK_ENABLE();
  __HAL_RCC_GPIOH_CLK_ENABLE();
  __HAL_RCC_GPIOJ_CLK_ENABLE();

  /*Configure GPIO pin Output Level */
  HAL_GPIO_WritePin(LCD_SS_GPIO_Port, LCD_SS_Pin, GPIO_PIN_RESET);

  /*Configure GPIO pin Output Level */
  HAL_GPIO_WritePin(GPIOG, OUT3_1V8_Pin|OUT1_1V8_Pin|OUT1_OD_Pin|OUT0_OD_Pin
                          |OUT0_1V8_Pin|OUT2_1V8_Pin, GPIO_PIN_RESET);

  /*Configure GPIO pin Output Level */
  HAL_GPIO_WritePin(GPIOI, OUT3_CONFIG_Pin|OUT1_CONFIG_Pin|OUT2_CONFIG_Pin|MCU_HEARTBEAT_Pin, GPIO_PIN_RESET);

  /*Configure GPIO pin Output Level */
  HAL_GPIO_WritePin(GPIOK, MCU_CTRL2_Pin|MCU_CTRL1_Pin, GPIO_PIN_RESET);

  /*Configure GPIO pin Output Level */
  HAL_GPIO_WritePin(GPIOF, BTN0_Pin|BTN1_Pin|BTN2_Pin|BTN3_Pin
                          |BTN4_Pin|BTN5_Pin, GPIO_PIN_RESET);

  /*Configure GPIO pin Output Level */
  HAL_GPIO_WritePin(GPIOH, OUT0_CONFIG_Pin|FRONT_LED_CTRL_Pin, GPIO_PIN_RESET);

  /*Configure GPIO pin Output Level */
  HAL_GPIO_WritePin(GPIOB, ZION_PWR_EN_Pin|EDL_EN_Pin|SPARE_SW_EN_Pin, GPIO_PIN_RESET);

  /*Configure GPIO pin Output Level */
  HAL_GPIO_WritePin(GPIOJ, MCU_CTRL0_Pin|UART_MUX_CTRL_Pin|LCD_EXTMODE_Pin|LCD_DISP_Pin, GPIO_PIN_RESET);

  /*Configure GPIO pin : LCD_SS_Pin */
  GPIO_InitStruct.Pin = LCD_SS_Pin;
  GPIO_InitStruct.Mode = GPIO_MODE_OUTPUT_PP;
  GPIO_InitStruct.Pull = GPIO_NOPULL;
  GPIO_InitStruct.Speed = GPIO_SPEED_FREQ_HIGH;
  HAL_GPIO_Init(LCD_SS_GPIO_Port, &GPIO_InitStruct);

  /*Configure GPIO pin : UI_INPUT11_Pin */
  GPIO_InitStruct.Pin = UI_INPUT11_Pin;
  GPIO_InitStruct.Mode = GPIO_MODE_INPUT;
  GPIO_InitStruct.Pull = GPIO_NOPULL;
  HAL_GPIO_Init(UI_INPUT11_GPIO_Port, &GPIO_InitStruct);

  /*Configure GPIO pins : OUT3_1V8_Pin OUT1_1V8_Pin OUT1_OD_Pin OUT0_OD_Pin
                           OUT0_1V8_Pin OUT2_1V8_Pin */
  GPIO_InitStruct.Pin = OUT3_1V8_Pin|OUT1_1V8_Pin|OUT1_OD_Pin|OUT0_OD_Pin
                          |OUT0_1V8_Pin|OUT2_1V8_Pin;
  GPIO_InitStruct.Mode = GPIO_MODE_OUTPUT_PP;
  GPIO_InitStruct.Pull = GPIO_NOPULL;
  GPIO_InitStruct.Speed = GPIO_SPEED_FREQ_LOW;
  HAL_GPIO_Init(GPIOG, &GPIO_InitStruct);

  /*Configure GPIO pin : UI_INPUT0_Pin */
  GPIO_InitStruct.Pin = UI_INPUT0_Pin;
  GPIO_InitStruct.Mode = GPIO_MODE_INPUT;
  GPIO_InitStruct.Pull = GPIO_NOPULL;
  HAL_GPIO_Init(UI_INPUT0_GPIO_Port, &GPIO_InitStruct);

  /*Configure GPIO pins : OUT3_CONFIG_Pin OUT1_CONFIG_Pin OUT2_CONFIG_Pin MCU_HEARTBEAT_Pin */
  GPIO_InitStruct.Pin = OUT3_CONFIG_Pin|OUT1_CONFIG_Pin|OUT2_CONFIG_Pin|MCU_HEARTBEAT_Pin;
  GPIO_InitStruct.Mode = GPIO_MODE_OUTPUT_PP;
  GPIO_InitStruct.Pull = GPIO_NOPULL;
  GPIO_InitStruct.Speed = GPIO_SPEED_FREQ_LOW;
  HAL_GPIO_Init(GPIOI, &GPIO_InitStruct);

  /*Configure GPIO pins : DWN_BTN_Pin SEL_BTN_Pin UP_BTN_Pin BACK_BTN_Pin */
  GPIO_InitStruct.Pin = DWN_BTN_Pin|SEL_BTN_Pin|UP_BTN_Pin|BACK_BTN_Pin;
  GPIO_InitStruct.Mode = GPIO_MODE_IT_FALLING;
  GPIO_InitStruct.Pull = GPIO_NOPULL;
  HAL_GPIO_Init(GPIOK, &GPIO_InitStruct);

  /*Configure GPIO pin : UI_INPUT1_Pin */
  GPIO_InitStruct.Pin = UI_INPUT1_Pin;
  GPIO_InitStruct.Mode = GPIO_MODE_INPUT;
  GPIO_InitStruct.Pull = GPIO_NOPULL;
  HAL_GPIO_Init(UI_INPUT1_GPIO_Port, &GPIO_InitStruct);

  /*Configure GPIO pins : UI_INPUT2_Pin UI_INPUT10_Pin UI_INPUT5_Pin UI_INPUT9_Pin
                           UI_INPUT4_Pin UI_INPUT3_Pin UI_INPUT7_Pin UI_INPUT8_Pin
                           UI_INPUT6_Pin */
  GPIO_InitStruct.Pin = UI_INPUT2_Pin|UI_INPUT10_Pin|UI_INPUT5_Pin|UI_INPUT9_Pin
                          |UI_INPUT4_Pin|UI_INPUT3_Pin|UI_INPUT7_Pin|UI_INPUT8_Pin
                          |UI_INPUT6_Pin;
  GPIO_InitStruct.Mode = GPIO_MODE_INPUT;
  GPIO_InitStruct.Pull = GPIO_NOPULL;
  HAL_GPIO_Init(GPIOD, &GPIO_InitStruct);

  /*Configure GPIO pins : MCU_CTRL2_Pin MCU_CTRL1_Pin */
  GPIO_InitStruct.Pin = MCU_CTRL2_Pin|MCU_CTRL1_Pin;
  GPIO_InitStruct.Mode = GPIO_MODE_OUTPUT_PP;
  GPIO_InitStruct.Pull = GPIO_NOPULL;
  GPIO_InitStruct.Speed = GPIO_SPEED_FREQ_LOW;
  HAL_GPIO_Init(GPIOK, &GPIO_InitStruct);

  /*Configure GPIO pins : BTN0_Pin BTN1_Pin BTN2_Pin BTN3_Pin
                           BTN4_Pin BTN5_Pin */
  GPIO_InitStruct.Pin = BTN0_Pin|BTN1_Pin|BTN2_Pin|BTN3_Pin
                          |BTN4_Pin|BTN5_Pin;
  GPIO_InitStruct.Mode = GPIO_MODE_OUTPUT_PP;
  GPIO_InitStruct.Pull = GPIO_NOPULL;
  GPIO_InitStruct.Speed = GPIO_SPEED_FREQ_LOW;
  HAL_GPIO_Init(GPIOF, &GPIO_InitStruct);

  /*Configure GPIO pins : OUT0_CONFIG_Pin FRONT_LED_CTRL_Pin */
  GPIO_InitStruct.Pin = OUT0_CONFIG_Pin|FRONT_LED_CTRL_Pin;
  GPIO_InitStruct.Mode = GPIO_MODE_OUTPUT_PP;
  GPIO_InitStruct.Pull = GPIO_NOPULL;
  GPIO_InitStruct.Speed = GPIO_SPEED_FREQ_LOW;
  HAL_GPIO_Init(GPIOH, &GPIO_InitStruct);

  /*Configure GPIO pins : ZION_PWR_EN_Pin EDL_EN_Pin SPARE_SW_EN_Pin */
  GPIO_InitStruct.Pin = ZION_PWR_EN_Pin|EDL_EN_Pin|SPARE_SW_EN_Pin;
  GPIO_InitStruct.Mode = GPIO_MODE_OUTPUT_PP;
  GPIO_InitStruct.Pull = GPIO_NOPULL;
  GPIO_InitStruct.Speed = GPIO_SPEED_FREQ_LOW;
  HAL_GPIO_Init(GPIOB, &GPIO_InitStruct);

  /*Configure GPIO pins : MCU_CTRL0_Pin UART_MUX_CTRL_Pin LCD_EXTMODE_Pin LCD_DISP_Pin */
  GPIO_InitStruct.Pin = MCU_CTRL0_Pin|UART_MUX_CTRL_Pin|LCD_EXTMODE_Pin|LCD_DISP_Pin;
  GPIO_InitStruct.Mode = GPIO_MODE_OUTPUT_PP;
  GPIO_InitStruct.Pull = GPIO_NOPULL;
  GPIO_InitStruct.Speed = GPIO_SPEED_FREQ_LOW;
  HAL_GPIO_Init(GPIOJ, &GPIO_InitStruct);

  /* EXTI interrupt init*/
  HAL_NVIC_SetPriority(EXTI4_IRQn, 5, 0);
  HAL_NVIC_EnableIRQ(EXTI4_IRQn);

  HAL_NVIC_SetPriority(EXTI9_5_IRQn, 5, 0);
  HAL_NVIC_EnableIRQ(EXTI9_5_IRQn);

}

/* USER CODE BEGIN 4 */

// Generic Error Handler for DevUI HAL hardware.
// char *msg is an error message that can be sent to the handler from the caller.
// err_param1 & err_param2 are additional error parameters that can be printed.
// For I2C errors, I2C device address in param1 and register address in param2.
void DevUI_Error_Handler(char *msg, HAL_StatusTypeDef ErrorCode, uint8_t err_param1, uint8_t err_param2, uint8_t critical_fault)
{
	__disable_irq();
	printf("ERROR: %s" " Code: %d Param1: 0x%x Param2: 0x%x\r\n", msg, ErrorCode, err_param1, err_param2);

	// Set error LED
	//errorLED.fault9 = true;
	// Use event group flag to indicate an error for the startErrorLED task.

	// If the fault is labeled as "critical" stay here.  Else keep running RTOS.
	if (critical_fault == true)
	{
	  while (1)
	  {
		  // HAL error occurred, sit here.  Do not continue to run OS.
	  }
	}
	else
	{
		__enable_irq();
		return;
	}
}

int __io_putchar(int ch)
{
	HAL_UART_Transmit(&huart7, (uint8_t *)&ch, 1, 100);

	return ch;
}

void outputGPIOBufInitialization(){
	memset(gpioOutputState,0,sizeof(gpioOutputState));
	setOutputGPIOState(outputGPIOs.odOut_0, ON); //set OD to high impediance
	setOutputGPIOState(outputGPIOs.odOut_1, ON); //set OD to high impediance
	gpioOutputState[outputGPIOs.odOut_0]=1;
	gpioOutputState[outputGPIOs.odOut_1]=1;
}

void setOutputGPIOState(int gpio, int state){

	if(gpio == outputGPIOs.configOut_0){
		HAL_GPIO_WritePin(GPIOH,OUT0_CONFIG_Pin,state);
		gpioOutputState[outputGPIOs.configOut_0] = state;
	}

	else if(gpio == outputGPIOs.configOut_1){
		HAL_GPIO_WritePin(GPIOI,OUT1_CONFIG_Pin,state);
		gpioOutputState[outputGPIOs.configOut_1] = state;
	}

	else if(gpio == outputGPIOs.configOut_2){
		HAL_GPIO_WritePin(GPIOI,OUT2_CONFIG_Pin,state);
		gpioOutputState[outputGPIOs.configOut_2] = state;
	}

	else if(gpio == outputGPIOs.configOut_3){
		HAL_GPIO_WritePin(GPIOI,OUT3_CONFIG_Pin,state);
		gpioOutputState[outputGPIOs.configOut_3] = state;
	}

	else if(gpio == outputGPIOs.mcu3V3_0){
		HAL_GPIO_WritePin(GPIOJ,MCU_CTRL0_Pin,state);
		gpioOutputState[outputGPIOs.mcu3V3_0] = state;
	}

	else if(gpio == outputGPIOs.mcu3V3_1){
		HAL_GPIO_WritePin(GPIOK,MCU_CTRL1_Pin,state);
		gpioOutputState[outputGPIOs.mcu3V3_1] = state;
	}

	else if(gpio == outputGPIOs.mcu3V3_2){
		HAL_GPIO_WritePin(GPIOK,MCU_CTRL2_Pin,state);
		gpioOutputState[outputGPIOs.mcu3V3_2] = state;
	}

	else if(gpio == outputGPIOs.mcu3V3_3){
		HAL_GPIO_WritePin(GPIOJ,UART_MUX_CTRL_Pin,state);
		gpioOutputState[outputGPIOs.mcu3V3_3] = state;
	}

	else if(gpio == outputGPIOs.out1V8_0){
		HAL_GPIO_WritePin(GPIOG,OUT0_1V8_Pin,state);
		gpioOutputState[outputGPIOs.out1V8_0] = state;
	}

	else if(gpio == outputGPIOs.out1V8_1){
		HAL_GPIO_WritePin(GPIOG,OUT1_1V8_Pin,state);
		gpioOutputState[outputGPIOs.out1V8_1] = state;
	}

	else if(gpio == outputGPIOs.out1V8_2){
		HAL_GPIO_WritePin(GPIOG,OUT2_1V8_Pin,state);
		gpioOutputState[outputGPIOs.out1V8_2] = state;
	}

	else if(gpio == outputGPIOs.out1V8_3){
		HAL_GPIO_WritePin(GPIOG,OUT3_1V8_Pin,state);
		gpioOutputState[outputGPIOs.out1V8_3] = state;
	}

	else if(gpio == outputGPIOs.odOut_0){
		HAL_GPIO_WritePin(GPIOG,OUT0_OD_Pin,state);
		gpioOutputState[outputGPIOs.odOut_0] = state;
	}

	else if(gpio == outputGPIOs.odOut_1){
		HAL_GPIO_WritePin(GPIOG,OUT1_OD_Pin,state);
		gpioOutputState[outputGPIOs.odOut_1] = state;
	}
}

void debugUartTransmitChar(char *message){
	char uart_buf[200];
	int uart_buf_len;
	uart_buf_len = sprintf(uart_buf, message);
	HAL_UART_Transmit(&DEBUG_UART, (uint8_t *)uart_buf, uart_buf_len,100);
}
void debugUartTransmitStuff(char *message, int size){
	char uart_buf[200];
	int uart_buf_len;
	uart_buf_len = sprintf(uart_buf, message);
	HAL_UART_Transmit(&DEBUG_UART, (uint8_t *)uart_buf, size,100);
}
void uartTransmitInt(uint16_t *number, int uart){
	char uart_buf[80];
	int uart_buf_len;
	uart_buf_len = sprintf(uart_buf, "0x%x\r\n", number);
	if (uart == 7){
		HAL_UART_Transmit(&huart7, (uint8_t *)uart_buf, uart_buf_len,100);
	}

}
void uartTransmitFloat(float *number, int uart){
	char uart_buf[80];
	int uart_buf_len;
	uart_buf_len = sprintf(uart_buf, "%f\r\n", number);
	if (uart == 7){
		HAL_UART_Transmit(&huart7, (uint8_t *)uart_buf, uart_buf_len,100);
	}

}

uint8_t * readI2CRegister(uint8_t address, uint8_t reg, int bytes, int i2CBank){
	static uint8_t buf[20];
	HAL_StatusTypeDef ret;
	buf[0]=reg;
	char *err_msg;
  	if(i2CBank == 1){
  		ret = HAL_I2C_Master_Transmit(&hi2c1, address, buf, 1, HAL_MAX_DELAY);
  		err_msg = "Failed I2C Read (Transmit) bank 1.";
  	}
  	else if(i2CBank == 2){
  		ret = HAL_I2C_Master_Transmit(&hi2c2, address, buf, 1, HAL_MAX_DELAY);
  		err_msg = "Failed I2C Read (Transmit) bank 2.";
  	}
  	else if(i2CBank == 3){
  		ret = HAL_I2C_Master_Transmit(&hi2c3, address, buf, 1, HAL_MAX_DELAY);
  		err_msg = "Failed I2C Read (Transmit) bank 3.";
  	}
  	else if(i2CBank == 4){
  		ret = HAL_I2C_Master_Transmit(&hi2c4, address, buf, 1, HAL_MAX_DELAY);
  		err_msg = "Failed I2C Read (Transmit) bank 4.";
  	}
	  if ( ret != HAL_OK ) {
		  	  DevUI_Error_Handler(err_msg, ret, address, reg, false);
	          return (uint8_t*)0xfe;
	        }
	  else {
		  if(i2CBank == 1){
				ret = HAL_I2C_Master_Receive(&hi2c1, address, buf, bytes, HAL_MAX_DELAY);
				err_msg = "Failed I2C Read (Receive) bank 1.";
			}
			else if(i2CBank == 2){
				ret = HAL_I2C_Master_Receive(&hi2c2, address, buf, bytes, HAL_MAX_DELAY);
				err_msg = "Failed I2C Read (Receive) bank 2.";
			}
			else if(i2CBank == 3){
				ret = HAL_I2C_Master_Receive(&hi2c3, address, buf, bytes, HAL_MAX_DELAY);
				err_msg = "Failed I2C Read (Receive) bank 3.";
			}
			else if(i2CBank == 4){
				ret = HAL_I2C_Master_Receive(&hi2c4, address, buf, bytes, HAL_MAX_DELAY);
				err_msg = "Failed I2C Read (Receive) bank 4.";
			}
		  if ( ret != HAL_OK ) {
			  	  DevUI_Error_Handler(err_msg, ret, address, reg, false);
		          return (uint8_t*)0xfe;
		        }
		  else{
			  //uartTransmitInt(buf[0],7);
			  return buf;
		  }
}
}
int writeI2CRegister(uint8_t address, uint8_t reg, uint8_t * bytes, int numBytes, int i2CBank){
  	uint8_t buf[20];
  	HAL_StatusTypeDef ret;
  	buf[0]=reg;
  	int x = 0;
  	char *err_msg;
  	for (x=0;x<(sizeof(bytes)-1);x++){
  		buf[1+x] = bytes[x];
  	}
  	if(i2CBank == 1){
  		ret = HAL_I2C_Master_Transmit(&hi2c1, address, buf, numBytes+1, HAL_MAX_DELAY);
  		err_msg = "Failed I2C write bank 1.";
  	}
  	else if(i2CBank == 2){
  		ret = HAL_I2C_Master_Transmit(&hi2c2, address, buf, numBytes+1, HAL_MAX_DELAY);
  		err_msg = "Failed I2C write bank 2.";
  	}
  	else if(i2CBank == 3){
  		ret = HAL_I2C_Master_Transmit(&hi2c3, address, buf, numBytes+1, HAL_MAX_DELAY);
  		err_msg = "Failed I2C write bank 3.";
  	}
  	else if(i2CBank == 4){
  		ret = HAL_I2C_Master_Transmit(&hi2c4, address, buf, numBytes+1, HAL_MAX_DELAY);
  		err_msg = "Failed I2C write bank 4.";
  	}
  	if (ret != HAL_OK)
  	{
  		DevUI_Error_Handler(err_msg, ret, address, reg, false);
  		return ret;
  	}
  	else
  	{
  		return HAL_OK;
  	}
}
void configureLEDDriver(){
	uint8_t currentMultiplier = 0b00000001;
	static uint8_t* clear[1];
	clear[0]=0x0;
	uint8_t * buf;
	//reduce the current multiplier to set brightness lower. See if this works. If not, we can work with PWM.
	writeI2CRegister(LED.address, LED.iref_reg, (uint8_t*)currentMultiplier,1,LED.i2cBank);
	buf = readI2CRegister(LED.address,LED.iref_reg,1,LED.i2cBank);
	//uartTransmitInt(buf[0],7);
	//Turn on oscillator. Must be turned on before LED driver functions
	writeI2CRegister(LED.address,LED.mode0_reg,(uint8_t*)LED.mode0_oscon_value,1,LED.i2cBank);
	//clear the default state of the led register.
	writeI2CRegister(LED.address,LED.led0_reg,(uint8_t*)clear,1,LED.i2cBank);
	writeI2CRegister(LED.address,LED.led1_reg,(uint8_t*)clear,1,LED.i2cBank);
	writeI2CRegister(LED.address,LED.led2_reg,(uint8_t*)clear,1,LED.i2cBank);
	writeI2CRegister(LED.address,LED.led3_reg,(uint8_t*)clear,1,LED.i2cBank);
	//set the PWM for the tri-color led. Thing is bright so PWM is very low.
	writeI2CRegister(LED.address,LED.led7_pwm,(uint8_t*)LED.pwm,1,LED.i2cBank);
	writeI2CRegister(LED.address,LED.led8_pwm,(uint8_t*)LED.pwm,1,LED.i2cBank);
	writeI2CRegister(LED.address,LED.led9_pwm,(uint8_t*)LED.pwm,1,LED.i2cBank);
}

//Configure & set RGB LED
void setRGBLED(uint8_t R, uint8_t G, uint8_t B)
{
	setErrorLED(RED, R);
	setErrorLED(GREEN, G);
	setErrorLED(BLUE, B);

	return;
}

//Configures specified LED to either fully on or off.
void setErrorLED(int led,_Bool change){
	const uint8_t led0 = 0b00000001;
	const uint8_t led1 = 0b00000100;
	const uint8_t led2 = 0b00010000;
	const uint8_t led3 = 0b01000000;
	const uint8_t led0_pwm = 0b00000010;
	const uint8_t led1_pwm = 0b00001000;
	const uint8_t led2_pwm = 0b00100000;
	const uint8_t led3_pwm = 0b10000000;
  	uint8_t* ledRegisterContents;
  	int ledBitNumber;
  	uint8_t ledRegister;
	if(led <4){
		ledRegister = LED.led0_reg;
		ledBitNumber=led;
	}
	else if(led <8){
		ledRegister = LED.led1_reg;
		ledBitNumber=led-4;
	}
	else if(led <12){
		ledRegister = LED.led2_reg;
		ledBitNumber=led-8;
	}
	else{ //put this in to humor those who want to try using unconnected LEDs
		ledRegister = LED.led3_reg;
		ledBitNumber=led-12;
	}
	ledRegisterContents = readI2CRegister(LED.address,ledRegister, 1, LED.i2cBank);
	switch(ledBitNumber){

	case 0:
		if(change){
			if(led == 8){
				ledRegisterContents[0] |= led0_pwm;
			}
			else{
				ledRegisterContents[0] |= led0;
			}
		}
		else{
			if(led == 8){
				ledRegisterContents[0] &= ~led0_pwm;
			}
			else{
				ledRegisterContents[0] &= ~led0;
			}
		}
		break;

	case 1:
		if(change){
			if(led == 9){
				ledRegisterContents[0] |= led1_pwm;
			}
			else{
				ledRegisterContents[0] |= led1;
			}
		}
		else{
			if(led == 9){
				ledRegisterContents[0] &= ~led1_pwm;
			}
			else{
				ledRegisterContents[0] &= ~led1;
			}
		}
		break;

	case 2:
		if(change){
				ledRegisterContents[0] |= led2;
		}
		else{

			ledRegisterContents[0] &= ~led2;
		}
		break;

	case 3:
		if(change){
			if(led == 7){
				ledRegisterContents[0] |= led3_pwm;
			}
			else{
				ledRegisterContents[0] |= led3;
			}
		}
		else{
			if(led == 7){
				ledRegisterContents[0] &= ~led3_pwm;
			}
			else{
				ledRegisterContents[0] &= ~led3;
			}
		}
		break;
	}
	writeI2CRegister(LED.address,ledRegister,ledRegisterContents,1,LED.i2cBank);
	ledRegisterContents = readI2CRegister(LED.address,ledRegister, 1, LED.i2cBank);
}

float* getADCValues(){
	//intialize a static float array to return from the method. Make static to avoid the data changing on return
	static float adcValues[21];
	//make an integer array to store the adc counts. ADC counts are out of 4096
	int avgADCCounterValues[21];
	//empty the integer array
	memset(avgADCCounterValues, 0, sizeof(avgADCCounterValues));
	int adcChannelCounter,avgCounter,adcIndex;
	//variables to denote what interval the data in the adc buffers repeats. ADC format is [data0, 0x00, data1, 0x00...]
	//the interval is (#ofchannels activated on bank) * 2
	int adc1DataRepeat=22;
	int adc2DataRepeat=8;
	int adc3DataRepeat=12;
	//iterate through all 21 adc channels...
	for(adcChannelCounter=0;adcChannelCounter<21;adcChannelCounter++){
		//for the first channels of the adc banks (ADC Bank 1's first channel is ADC3, ADC bank 2's first channel is ADC0, ADC bank 3's first channel is adc2
		if((adcChannelCounter==Adc.adc0) || (adcChannelCounter==Adc.adc2) || (adcChannelCounter==Adc.adc3)){
			//first data entry for each buffer will be the data for these adcs
			adcIndex=0;
		}
		//for the second channels of the adc banks (ADC Bank 1's second channel is ADC4, ADC bank 2's second channel is ADC1, ADC bank 3's second channel is adc14
		else if((adcChannelCounter==Adc.adc1) || (adcChannelCounter==Adc.adc14) || (adcChannelCounter==Adc.adc4)){
			adcIndex=2;
		}
		//for the third channels of the adc banks (ADC Bank 1's third channel is ADC5, ADC bank 2's third channel is spareSpiADC, ADC bank 3's third channel is adc15
		else if((adcChannelCounter==Adc.spareSpiADC) || (adcChannelCounter==Adc.adc15) || (adcChannelCounter==Adc.adc5)){
			adcIndex=4;
		}
		//for the fourth channels of the adc banks (ADC Bank 1's fourth channel is adc6, ADC bank 2's fourth channel is spareUARTADC, ADC bank 3's fourth channel is configADC
		else if((adcChannelCounter == Adc.spareUartADC) || (adcChannelCounter==Adc.configADC) || (adcChannelCounter==Adc.adc6)){
			adcIndex=6;
		}
		//for the fifth channels of the adc banks (ADC Bank 1's fifth channel is ADC7, ADC bank 3's fifth channel is zionADC
		else if((adcChannelCounter==Adc.zionADC) || (adcChannelCounter==Adc.adc7)){
			adcIndex=8;
		}
		//for the sixth channels of the adc banks (ADC Bank 1's sixth channel is ADC8, ADC bank 3's sixth channel is spareI2cADC
		else if((adcChannelCounter == Adc.spareI2cADC) || (adcChannelCounter==Adc.adc8)){
			adcIndex=10;
		}
		//for the seventh channels of the adc banks (ADC Bank 1's seventh channel is ADC9)
		else if(adcChannelCounter==Adc.adc9){
			adcIndex=12;
		}
		//for the eighth channels of the adc banks (ADC Bank 1's eighth channel is ADC10)
		else if(adcChannelCounter==Adc.adc10){
			adcIndex=14;
		}
		//for the nineth channels of the adc banks (ADC Bank 1's nineth channel is ADC11)
		else if(adcChannelCounter==Adc.adc11){
			adcIndex=16;
		}
		//for the tenth channels of the adc banks (ADC Bank 1's tenth channel is ADC12)
		else if(adcChannelCounter==Adc.adc12){
			adcIndex=18;
		}
		//for the eleventh channels of the adc banks (ADC Bank 1's eleventh channel is ADC13)
		else{
			adcIndex=20;
		}
		//for the channels that belong to the second ADC bank
		if((adcChannelCounter == Adc.adc0) || (adcChannelCounter == Adc.adc1) || (adcChannelCounter == Adc.spareSpiADC) || (adcChannelCounter == Adc.spareUartADC)){
			//parse through the buffers to grab enough values to make the asked for average amount
			for(avgCounter=0;avgCounter<ADC_AVG_COUNT;avgCounter++){
				//adjust the index to match the next data point in the buffer
				int shiftedIndex = adcIndex + (adc2DataRepeat*avgCounter);
				//add it to the rolling average count
				avgADCCounterValues[adcChannelCounter]+=adc2_buf[shiftedIndex];
				if (avgCounter == (ADC_AVG_COUNT-1)){
					//at the end, divide the total amount to get our averaged Value
					avgADCCounterValues[adcChannelCounter] = avgADCCounterValues[adcChannelCounter]/ADC_AVG_COUNT;
				}
			}
		}
		//for the channels that belong to the third ADC bank
		else if((adcChannelCounter == Adc.adc2) || (adcChannelCounter == Adc.adc14) || (adcChannelCounter == Adc.adc15) || (adcChannelCounter == Adc.configADC) || (adcChannelCounter == Adc.zionADC) || (adcChannelCounter == Adc.spareI2cADC)){
			for(avgCounter=0;avgCounter<ADC_AVG_COUNT;avgCounter++){
				int shiftedIndex = adcIndex + (adc3DataRepeat*avgCounter);
				avgADCCounterValues[adcChannelCounter]+=adc3_buf[shiftedIndex];
				if (avgCounter == (ADC_AVG_COUNT-1)){
					avgADCCounterValues[adcChannelCounter] = avgADCCounterValues[adcChannelCounter]/ADC_AVG_COUNT;
				}
			}
		}
		//for the channels that belong to the first ADC bank
		else{
			for(avgCounter=0;avgCounter<ADC_AVG_COUNT;avgCounter++){
				int shiftedIndex = adcIndex + (adc1DataRepeat*avgCounter);
				avgADCCounterValues[adcChannelCounter]+=adc1_buf[shiftedIndex];
				if (avgCounter == (ADC_AVG_COUNT-1)){
					avgADCCounterValues[adcChannelCounter] = avgADCCounterValues[adcChannelCounter]/ADC_AVG_COUNT;
				}
			}
		}
	}
	//for adc inputs with names ADC#, true value is found by taking the average, multiplying it by the divisor(3.3/4096), and then multiplying by the resistor divider (3)
	adcValues[Adc.adc0] = (avgADCCounterValues[Adc.adc0] * Adc.adcDivisor) * Adc.adcResistorDivider;
	adcValues[Adc.adc1] = (avgADCCounterValues[Adc.adc1] * Adc.adcDivisor) * Adc.adcResistorDivider;
	adcValues[Adc.adc2] = (avgADCCounterValues[Adc.adc2] * Adc.adcDivisor) * Adc.adcResistorDivider;
	adcValues[Adc.adc3] = (avgADCCounterValues[Adc.adc3] * Adc.adcDivisor) * Adc.adcResistorDivider;
	adcValues[Adc.adc4] = (avgADCCounterValues[Adc.adc4] * Adc.adcDivisor) * Adc.adcResistorDivider;
	adcValues[Adc.adc5] = (avgADCCounterValues[Adc.adc5] * Adc.adcDivisor) * Adc.adcResistorDivider;
	adcValues[Adc.adc6] = (avgADCCounterValues[Adc.adc6] * Adc.adcDivisor) * Adc.adcResistorDivider;
	adcValues[Adc.adc7] = (avgADCCounterValues[Adc.adc7] * Adc.adcDivisor) * Adc.adcResistorDivider;
	adcValues[Adc.adc8] = (avgADCCounterValues[Adc.adc8] * Adc.adcDivisor) * Adc.adcResistorDivider;
	adcValues[Adc.adc9] = (avgADCCounterValues[Adc.adc9] * Adc.adcDivisor) * Adc.adcResistorDivider;
	adcValues[Adc.adc10] = (avgADCCounterValues[Adc.adc10] * Adc.adcDivisor) * Adc.adcResistorDivider;
	adcValues[Adc.adc11] = (avgADCCounterValues[Adc.adc11] * Adc.adcDivisor) * Adc.adcResistorDivider;
	adcValues[Adc.adc12] = (avgADCCounterValues[Adc.adc12] * Adc.adcDivisor) * Adc.adcResistorDivider;
	adcValues[Adc.adc13] = (avgADCCounterValues[Adc.adc13] * Adc.adcDivisor) * Adc.adcResistorDivider;
	adcValues[Adc.adc14] = (avgADCCounterValues[Adc.adc14] * Adc.adcDivisor) * Adc.adcResistorDivider;
	adcValues[Adc.adc15] = (avgADCCounterValues[Adc.adc15] * Adc.adcDivisor) * Adc.adcResistorDivider;
	//for other adc inputs, true value is found by taking the average, multiplying it by the divisor(3.3/4096), and then multiplying by the resistor divider (2)
	adcValues[Adc.spareSpiADC] = (avgADCCounterValues[Adc.spareSpiADC] * Adc.adcDivisor) * Adc.systemResistorDivider;
	adcValues[Adc.spareUartADC] = (avgADCCounterValues[Adc.spareUartADC] * Adc.adcDivisor) * Adc.systemResistorDivider;
	adcValues[Adc.configADC] = (avgADCCounterValues[Adc.configADC] * Adc.adcDivisor) * Adc.systemResistorDivider;
	adcValues[Adc.zionADC] = (avgADCCounterValues[Adc.zionADC] * Adc.adcDivisor) * Adc.systemResistorDivider;
	adcValues[Adc.spareI2cADC] = (avgADCCounterValues[Adc.spareI2cADC] * Adc.adcDivisor) * Adc.systemResistorDivider;
	return adcValues;
}

void setVoltageMux(int comChannel, int voltageChannel, int clear){
	uint8_t dataWriteCOMA[1];
	uint8_t dataWriteCOMB[1];
	if((comChannel) & (!clear)){
		dataWriteCOMA[0] = socI2cVoltageMux.clearSwitches;
		dataWriteCOMB[0]= voltageChannel;
	}
	else if((!comChannel) & (!clear)){
		dataWriteCOMA[0] = voltageChannel;
		dataWriteCOMB[0]= socI2cVoltageMux.clearSwitches;
	}
	else{
		dataWriteCOMA[0] = socI2cVoltageMux.clearSwitches;
		dataWriteCOMB[0]= socI2cVoltageMux.clearSwitches;
	}
	writeI2CRegister(socI2cVoltageMux.address, socI2cVoltageMux.CMD_A_reg, dataWriteCOMA,sizeof(dataWriteCOMA), socI2cVoltageMux.i2cBank);
	writeI2CRegister(socI2cVoltageMux.address, socI2cVoltageMux.CMD_B_reg, dataWriteCOMB,sizeof(dataWriteCOMB), socI2cVoltageMux.i2cBank);
}

int detectSocVoltageMux(){
	int voltageMuxPresent = 0;
	if(HAL_I2C_IsDeviceReady(&SOC_I2C, socI2cVoltageMux.address, 2, 100)== HAL_OK){
			voltageMuxPresent = 1;
		}
	return voltageMuxPresent;
}

//// Called when first half of buffer is filled
//void HAL_ADC_ConvHalfCpltCallback(ADC_HandleTypeDef* hadc) {
//}
//
//// Called when buffer is completely filled
void HAL_ADC_ConvCpltCallback(ADC_HandleTypeDef* hadc) {
}

void winbondSPIDeviceIDRead(SPI_HandleTypeDef hspi, uint8_t* data){
	uint8_t dataSent[1] = {0x9f};
	SPARE_SS_ON;
	HAL_SPI_TransmitReceive(&hspi, (uint8_t*)dataSent, data,4,100);
	SPARE_SS_OFF;
}

void spareUartTransmitRead(char *message){
	char uart_buf[200];
	char uart_receive_buf[200];
	int uart_buf_len;
	uart_buf_len = sprintf(uart_buf, message);
	HAL_UART_Transmit(&SPARE_UART,(uint8_t *)uart_buf, uart_buf_len,100);
	//HAL_UART_Receive(&SPARE_UART,(uint8_t*)uart_receive_buf, sizeof(uart_receive_buf),1000);
}

uint8_t debugUartParser(){
	int x;
	uint8_t  key_uint8[4];
	uint8_t var_Seen[4];
	key_uint8[0] = (uint8_t)'G';
	key_uint8[1] = (uint8_t)'I';
	key_uint8[2] = (uint8_t)'V';
	key_uint8[3] = (uint8_t)'E';
	//memcpy(key_uint8,(const uint8_t*)key, 4);
	x=5;

	for(x=0;x<sizeof(debug_Uart_RX_Buf);x++){
		if(debug_Uart_RX_Buf[x]==key_uint8[0]){
			var_Seen[0] = 1;
		}
		else if(debug_Uart_RX_Buf[x]==key_uint8[1] && var_Seen[0]){
			var_Seen[1] = 1;
		}
		else if(debug_Uart_RX_Buf[x]==key_uint8[2] && var_Seen[1]){
			var_Seen[2] = 1;
		}
		else if(debug_Uart_RX_Buf[x]==key_uint8[3] && var_Seen[2]){
			var_Seen[3] = 1;
			break;
		}
		else{
			memset(var_Seen,0x00,sizeof(var_Seen));
		}
	}
	if(var_Seen[3]){
		memset(debug_Uart_RX_Buf,0x00,sizeof(debug_Uart_RX_Buf));
		return true;
	}
	else{
		return false;
	}
}

uint8_t * socUartParser(){
	int x;
	uint8_t  key_uint8[4];
	static uint8_t var_Seen[15];
	memset(var_Seen,0x00,sizeof(var_Seen));
	static uint8_t failure[15];
	memset(failure, 0xff,sizeof(failure));
	key_uint8[0] = (uint8_t)'F';
	key_uint8[1] = (uint8_t)'F';
	key_uint8[2] = (uint8_t)'U';
	key_uint8[3] = (uint8_t)':';
	//memcpy(key_uint8,(const uint8_t*)key, 4);
	x=5;
	int ffuBytes=4;
	for(x=0;x<sizeof(soc_Uart_RX_Buf);x++){
		if(soc_Uart_RX_Buf[x]==key_uint8[0] && var_Seen[0]==0){
			var_Seen[0] = 1;
		}
		else if(soc_Uart_RX_Buf[x]==key_uint8[1] && var_Seen[0]){
			var_Seen[1] = 1;
		}
		else if(soc_Uart_RX_Buf[x]==key_uint8[2] && var_Seen[1]){
			var_Seen[2] = 1;
		}
		else if(soc_Uart_RX_Buf[x]==key_uint8[3] && var_Seen[2]){
			var_Seen[3] = 1;
			//break;
		}
		else if(var_Seen[3]){
			if(ffuBytes<sizeof(var_Seen)){
				var_Seen[ffuBytes] = soc_Uart_RX_Buf[x];
				ffuBytes++;
			}
			else{
				break;
			}
		}
		else{
			memset(var_Seen,0x00,sizeof(var_Seen));
		}
	}
	if(var_Seen[3]){

		memset(soc_Uart_RX_Buf,0x00,sizeof(soc_Uart_RX_Buf));
		return var_Seen;
	}
	else{
		return failure;
	}
}
/* USER CODE END 4 */

void startHeartbeat(void *argument)
{
  /* USER CODE BEGIN 5 */
  /* Infinite loop */
	int x=0;
  for(;;)
  {
	  HAL_GPIO_TogglePin(GPIOI,MCU_HEARTBEAT_Pin);
	  //display needs to alternate EXCOMM to avoid burn in.
	  if(x){
		  LCD_EXCOMM_L;
		  x=0;
	  }
	  else{
		  LCD_EXCOMM_H
		  x=1;
	  }
	  //spareUartTransmitRead("YOYOYO!\r\n");
	  osDelay(500);
  }

  /* USER CODE END 5 */
}

void startADCRead(void *argument)
{
  /* USER CODE BEGIN startADCRead */
  HAL_StatusTypeDef Status = HAL_OK;
  /* Infinite loop */
  for(;;)
  {
	  // Clear HAL fault LED
	  //errorLED.fault9 = false;
	  //empty out the data ready variables and the adc3_bufs
	  adcStates.adcBank1Finished=0;
	  adcStates.adcBank2Finished=0;
	  adcStates.adcBank3Finished=0;
	//memset(adcRestart,0,sizeof(adcRestart));
	memset(adc1_buf, 0, sizeof(adc1_buf));
	memset(adc2_buf, 0, sizeof(adc2_buf));
	memset(adc3_buf, 0, sizeof(adc3_buf));
	//restart the DMAs.
	HAL_ADC_Start_DMA(&hadc1, (uint32_t*)adc1_buf, ADC_BUF_LEN);
	if (Status != HAL_OK)
	{
		DevUI_Error_Handler("ADC1 Failed read.", Status, 0, 0, true);
	}
	HAL_ADC_Start_DMA(&hadc2, (uint32_t*)adc2_buf, ADC_BUF_LEN);
	if (Status != HAL_OK)
	{
		DevUI_Error_Handler("ADC2 Failed read.", Status, 0, 0, true);
	}
	HAL_ADC_Start_DMA(&hadc3, (uint32_t*)adc3_buf, ADC_BUF_LEN);
	if (Status != HAL_OK)
	{
		DevUI_Error_Handler("ADC3 Failed read.", Status, 0, 0, true);
	}
    osDelay(600);
  }
  /* USER CODE END startADCRead */
}

void GetDaScreenBlink(void *argument)
{
  /* USER CODE BEGIN GetDaScreenBlink */
  /* Infinite loop */
	 initializeDisplay();
	 uint32_t ulNotifiedValue;
	 uint8_t button_val = 0;
	 uint8_t menu_val = 0;
	 uint8_t running_menu = 0;

	   for(;;)
	   {
	 	  ulNotifiedValue = 0;
	 	  xTaskNotifyWait(NOTIFY_NOCLEAR, NOTIFY_CLEARALL, &ulNotifiedValue, portMAX_DELAY);
	 	  // button press decode
	 	  button_val = (ulNotifiedValue & NOTIFY_BTN_MASK);
	 	  menu_val = ((ulNotifiedValue & NOTIFY_MENU_MASK) >> NOTIFY_MENU_BIT);
	 	  running_menu = ((ulNotifiedValue & NOTIFY_RUN_MENU_MASK) >> NOTIFY_MENU_RUN_BIT);
	 	  //if(!(x%400)){
	 	//	  bootButtons.btn5=1;
	 		//  x++;
	 	  //}
	 	  //setVoltageMux(COMA,socI2cVoltageMux.enableSW2,0);

	 	  //readI2c = parseZionEEPROM(SOC_ADDRESS);
	 	  //int blah = *(readI2c+4);
	 	  int x = 0;
//	 	  HAL_GPIO_WritePin(ZION_PWR_EN_GPIO_Port,ZION_PWR_EN_Pin,1);
//	 	  writeZionBinaries();
//	 	  readI2c = parseZionEEPROM(ASIC_ADDRESS);
//	 	  int blah = *(readI2c);
//	 	  blah = *(readI2c+2);
//	 	  blah = *(readI2c+3);
//	 	  //readI2c = parseZionEEPROM(DISPLAY_ADDRESS);
	 	  //blah = *(readI2c+4);
//	 	  clearEEPROM(SOC_ADDRESS);
//	 	  readI2c = parseZionEEPROM(SOC_ADDRESS);
//	 	  blah = *(readI2c+5);
	 	  //clearEEPROM(SOC_ADDRESS);
	 	  //clearEEPROM(ASIC_ADDRESS);
	 	  //clearEEPROM(DISPLAY_ADDRESS);
//	 	  readDataFromEEPROM((uint8_t*)readI2c,SOC_ADDRESS,0x0,sizeof(readI2c), 500);
//	 	  printf(readI2c[0]);
//	 	  readDataFromEEPROM((uint8_t*)readI2c,ASIC_ADDRESS,0x0,sizeof(readI2c), 500);
//	 	  printf(readI2c[0]);
//	 	  readDataFromEEPROM((uint8_t*)readI2c,DISPLAY_ADDRESS,0x0,sizeof(readI2c), 500);
//	 	  printf(readI2c[0]);
	 	  x = 0;

	 	  //binaryToArray(readBinary,"Kanu");
//	 	  printf(*readI2c);
	 //	  printf("uNotifiedValue %d\r\n", ulNotifiedValue);
	 //	  printf("running_menu: %d\r\n", running_menu);
	 //	  printf("highlighed menu: %d\n\r", menu_val);
	 //	  printf("button_press: %d\r\n", button_val);

	 	  // If the BACK button was pressed, just run the SEL button case with the previous menu

		  switch(running_menu)
		  {
		  case BOOT_MENU:
		  {
			  //printf("BOOT_MENU\r\n");
			  drawBootMenu(menu_val, button_val, running_menu);
			  //uartTransmitChar("switch BOOT_MENU\r\n",7);
			  break;
		  }
		  case MAIN_MENU:
		  {
			  //printf("MAIN_MENU\r\n");
			  drawMainMenu(menu_val);
			  //uartTransmitChar("switch MAIN_MENU\r\n",7);
			  break;
		  }
		  case STATUS_MENU:
		  {
			  //printf("STATUS_MENU\r\n");
			  drawStatusMenu(menu_val);
			  //uartTransmitChar("switch STATUS_MENU\r\n",7);
			  break;
		  }
		  case SYSTEM_INFO_MENU:
		  {
			  //printf("SYSTEM INFO MENU\r\n");
			  //uartTransmitChar("switch SYSTEM INFO_MENU\r\n",7);
			  drawSystemInfoMenu(menu_val);
			  break;
		  }
		  }
	 	  osDelay(100);
	   }
  /* USER CODE END GetDaScreenBlink */
}

void startGpioInputRead(void *argument)
{
  /* USER CODE BEGIN startGpioInputRead */
  /* Infinite loop */
  for(;;)
  {
	  gpioInputBuf[inputGPIOs.input0] = HAL_GPIO_ReadPin(UI_INPUT0_GPIO_Port,UI_INPUT0_Pin);
	  gpioInputBuf[inputGPIOs.input1] = HAL_GPIO_ReadPin(UI_INPUT1_GPIO_Port,UI_INPUT1_Pin);
	  gpioInputBuf[inputGPIOs.input2] = HAL_GPIO_ReadPin(GPIOD,UI_INPUT2_Pin);
	  gpioInputBuf[inputGPIOs.input3] = HAL_GPIO_ReadPin(GPIOD,UI_INPUT3_Pin);
	  gpioInputBuf[inputGPIOs.input4] = HAL_GPIO_ReadPin(GPIOD,UI_INPUT4_Pin);
	  gpioInputBuf[inputGPIOs.input5] = HAL_GPIO_ReadPin(GPIOD,UI_INPUT5_Pin);
	  gpioInputBuf[inputGPIOs.input6] = HAL_GPIO_ReadPin(GPIOD,UI_INPUT6_Pin);
	  gpioInputBuf[inputGPIOs.input7] = HAL_GPIO_ReadPin(GPIOD,UI_INPUT7_Pin);
	  gpioInputBuf[inputGPIOs.input8] = HAL_GPIO_ReadPin(GPIOD,UI_INPUT8_Pin);
	  gpioInputBuf[inputGPIOs.input9] = HAL_GPIO_ReadPin(GPIOD,UI_INPUT9_Pin);
	  gpioInputBuf[inputGPIOs.input10] = HAL_GPIO_ReadPin(GPIOD,UI_INPUT10_Pin);
	  gpioInputBuf[inputGPIOs.input11] = HAL_GPIO_ReadPin(UI_INPUT11_GPIO_Port,UI_INPUT11_Pin);
	  osDelay(950);
  }
  /* USER CODE END startGpioInputRead */
}

void startNavigationTask(void *argument)
{
  /* USER CODE BEGIN startNavigationTask */
	uint8_t menu_highlight = MENU_TOP;	// variable indicates what menu item is currently being highlighted
	uint8_t	menu_run = MAIN_MENU;		// variable to track what menu is currently running
	uint8_t prev_menu = menu_run;		// variable to track what the previous menu running was, this is used for the BACK button
	uint8_t menu_Max_Items = MAX_MENU_ITEMS_MAIN_MENU;
	uint8_t prev_menu_highlight = menu_highlight; //variable to track previous menu highlight
//	int zionCleared=0;
	//uint8_t button_press = 1;
	// Clear button flags here

  /* Infinite loop */
  for(;;)
  {
	switch(inputButtonSet)
	{
	case UP:
	{
		if ((menu_highlight == MENU_TOP) || bootButtons.bootModeSet)
		{
			//do nothing
		}
		else
		{
			menu_highlight = menu_highlight - 1;
			// task notify the display task with UP and current highlighted item
			// task notification U32 bits defined as:
			// [0:3]: menu button flags [0]:UP, [1]:DWN, [2]:SEL, [3]:Reserved
			// [4:7]: menu indicator highlight flags
			// [8:11]: currently running menu flags
			xTaskNotify(DatScreenBlinkHandle, (UP | (menu_highlight << NOTIFY_MENU_BIT) | (menu_run << NOTIFY_MENU_RUN_BIT)), eSetValueWithoutOverwrite);
		}
		break;
	}
	case DWN:
	{
		if ((menu_highlight >= menu_Max_Items) || (bootButtons.bootModeSet))
		{
			//do nothing
		}
		else
		{
			menu_highlight = menu_highlight + 1;
			// task notify the display task with DWN and current highlighted item
			// task notification U32 bits defined as:
			// [0:3]: menu button flags [0]:UP, [1]:DWN, [2]:SEL, [3]:Reserved
			// [4:7]: menu selection flags
			// [8:11]: currently running menu flags
			// [12:15]: previously running menu flags
			xTaskNotify(DatScreenBlinkHandle, (DWN | (menu_highlight << NOTIFY_MENU_BIT) | (menu_run << NOTIFY_MENU_RUN_BIT)), eSetValueWithoutOverwrite);
		}
		break;
	}
	case BACK:
	{
		if(!(bootButtons.bootModeSet)){
			menu_run = prev_menu;
			menu_highlight = prev_menu_highlight; //set the highlight back to where it was for the previous menu.
		}
		// task notify the display task with SEL and what menu to run
		// task notification U32 bits defined as:
		// [0:3]: menu button flags [0]:UP, [1]:DWN, [2]:SEL, [3]:Reserved
		// [4:7]: menu selection flags
		// [8:11]: currently running menu flags
		// [12:15]: previously running menu flags
		xTaskNotify(DatScreenBlinkHandle, (BACK | (menu_highlight << NOTIFY_MENU_BIT) | (menu_run << NOTIFY_MENU_RUN_BIT)), eSetValueWithoutOverwrite);
		break;
	}
	case SEL:
	{
		if(menu_run==MAIN_MENU){
			prev_menu = menu_run;		// save currently running menu for BACK button
			menu_run = menu_highlight+1;	// update the currently running menu to what the user SELECTED. Requires +1 to match with menu values
			prev_menu_highlight = menu_highlight; //keep track of the previous menu's highlight for when back is pressed
			menu_highlight=MENU_TOP; //reset the menu highlight for the next menu
		}
//			printf("menu_run: %d\r\n", menu_run);
//			printf("prev_menu: %d\r\n", prev_menu);
//			printf("menu_run_adjust: %d\r\n", (menu_run << NOTIFY_MENU_RUN_BIT));
		// task notify the display task with SEL and what menu to run
		// task notification U32 bits defined as:
		// [0:3]: menu button flags [0]:UP, [1]:DWN, [2]:SEL, [3]:Reserved
		// [4:7]: menu selection flags
		// [8:11]: currently running menu flags
		// [12:15]: previously running menu flags
		xTaskNotify(DatScreenBlinkHandle, (SEL | (menu_highlight << NOTIFY_MENU_BIT) | (menu_run << NOTIFY_MENU_RUN_BIT)), eSetValueWithoutOverwrite);
		break;
	}
	default:
		// task notify the display task with no button press.  Just refresh the current running menu.
		xTaskNotify(DatScreenBlinkHandle, (NO_BTN_PRESS | (menu_highlight << NOTIFY_MENU_BIT) | (menu_run << NOTIFY_MENU_RUN_BIT)), eSetValueWithoutOverwrite);
		break;
	}
	//initialize the max indicator for each menu
	switch(menu_run){

	case BOOT_MENU:{
		menu_Max_Items = MAX_MENU_ITEMS_BOOT_MENU;
		break;
	}
	case MAIN_MENU:{
		menu_Max_Items = MAX_MENU_ITEMS_MAIN_MENU;
		break;
	}
	case STATUS_MENU:{
		menu_Max_Items = MAX_MENU_ITEMS_STATUS_MENU;
		break;
	}
	case SYSTEM_INFO_MENU:{
		menu_Max_Items = MAX_MENU_ITEMS_SYSTEM_INFO_MENU;
		break;
	}
	default:
		menu_Max_Items = MAX_MENU_ITEMS_BOOT_MENU;
		break;
	}
	inputButtonSet = NO_BTN_PRESS;
    osDelay(200);
  }

  /* USER CODE END startNavigationTask */
}

void startErrorLEDs(void *argument)
{
  /* USER CODE BEGIN startErrorLEDs */
  /* Infinite loop */
	int i2cCheck;
	uint8_t R;
	uint8_t G;
	uint8_t B;
	float * presentADCValues;

	// An array of voltage rails that are monitored for faults.  Each element maps to the apporpriate ADC channel for monitoring
	// PLATFORM TEMPLATE: edit this array to include the voltages that you would like to monitor for faults.  The names are defined in main.h
	uint8_t monitor_rails[] = {VSYS, VREG_BOB, VREG_S5A, VREG_S6C};

	// An array of falling edge fault thresholds for the voltage rails that are monitored for faults.  Size of the array and index for each fault should match the voltage name in monitor_rails[].
	double monitor_fault_thresholds[] = {VSYS_FLT, VREG_BOB_FLT, VREG_S5A_FLT, VREG_S6C_FLT};

	// An array of platform gpio inputs that are monitored for faults.  Each element maps to the appropriate STM GPIO input for monitoring
	// PLATFORM TEMPLATE: edit this array to include the voltages that you would like to monitor for faults.  The names are defined in main.h
	uint8_t monitor_gpio[] = {SOC_IN0, SOC_IN3, SOC_IN8, SOC_IN11};

	// An array of logic fault thresholds for the GPIO input rails that are monitored for faults.  The fault thresholds should match the mapping used in monitor_gpio[].
	uint8_t gpio_thresholds[] = {SOC_IN0_FLT, SOC_IN3_FLT, SOC_IN8_FLT, SOC_IN11_FLT};

	uint8_t * errorLEDptr;

  for(;;)
  {
	  int weAreAtlas = (ZION.SOC_BoardFab == ATLAS) || (ZION.ASIC_BoardFab == ATLAS) || (ZION.DISPLAY_BoardFab == ATLAS);
	  if(weAreAtlas){
		  atlasErrorLEDs();
	  }
	  else{
		  defaultErrorLEDs();
	  }
    osDelay(500);
  }
  /* USER CODE END startErrorLEDs */
}

void startZionRead(void *argument)
{
  /* USER CODE BEGIN startZionRead */
  /* Infinite loop */
	float * adcValuePointer;
	int * zionEEPROMPresent;
	int * zionHeaderData;
	int switchOn=0;
	float zionVoltage=77;

  for(;;)
  {
	  if(!ZION.zionFinished){
		  if (ADC_FINISHED){
			  adcValuePointer = getADCValues();
			  zionVoltage = *(adcValuePointer + Adc.zionADC);
		  }
		  if(zionVoltage != 77){
			  if(zionVoltage > 3.0 && (!switchOn)){
				  int runtime = (HAL_GetTick()/1000);
				  if(runtime > 3){
					  zionEEPROMPresent= zionEEPROMPresence();
					  if(*zionEEPROMPresent){
						  ZION.SOC_EEPROM_Detected = 1;
						  zionHeaderData = parseZionEEPROM(SOC_ADDRESS);
						  ZION.SOC_BoardID = *(zionHeaderData);
						  ZION.SOC_BoardFab = *(zionHeaderData+2);
						  ZION.SOC_Config = *(zionHeaderData+3);
					  }

					  if(*(zionEEPROMPresent+1)){
						  ZION.ASIC_EEPROM_Detected = 1;
						  zionHeaderData = parseZionEEPROM(ASIC_ADDRESS);
						  ZION.ASIC_BoardID = *(zionHeaderData);
						  ZION.ASIC_BoardFab = *(zionHeaderData+2);
						  ZION.ASIC_Config = *(zionHeaderData+3);

					  }
					  if(*(zionEEPROMPresent+2)){
						  ZION.DISPLAY_EEPROM_Detected = 1;
						  zionHeaderData = parseZionEEPROM(DISPLAY_ADDRESS);
						  ZION.DISPLAY_BoardID = *(zionHeaderData);
						  ZION.DISPLAY_BoardFab = *(zionHeaderData+2);
						  ZION.DISPLAY_Config = *(zionHeaderData+3);
					  }
					  ZION.zionFinished=1;
					  osThreadExit();
				  }
			  }
			  else{
				  if(!switchOn){
					  HAL_GPIO_WritePin(ZION_PWR_EN_GPIO_Port,ZION_PWR_EN_Pin,1);
					  ZION.zionSwitch = 1;
					  switchOn=1;
				  }
				  else{
					  zionEEPROMPresent= zionEEPROMPresence();
					  if(*zionEEPROMPresent){
						  ZION.SOC_EEPROM_Detected = 1;
						  zionHeaderData = parseZionEEPROM(SOC_ADDRESS);
						  ZION.SOC_BoardID = *(zionHeaderData);
						  ZION.SOC_BoardFab = *(zionHeaderData+2);
						  ZION.SOC_Config = *(zionHeaderData+3);
					  }
					  if(*(zionEEPROMPresent+1)){
						  ZION.ASIC_EEPROM_Detected = 1;
						  zionHeaderData = parseZionEEPROM(ASIC_ADDRESS);
						  ZION.ASIC_BoardID = *(zionHeaderData);
						  ZION.ASIC_BoardFab = *(zionHeaderData+2);
						  ZION.ASIC_Config = *(zionHeaderData+3);

					  }
					  if(*(zionEEPROMPresent+2)){
						  ZION.DISPLAY_EEPROM_Detected = 1;
						  zionHeaderData = parseZionEEPROM(DISPLAY_ADDRESS);
						  ZION.DISPLAY_BoardID = *(zionHeaderData);
						  ZION.DISPLAY_BoardFab = *(zionHeaderData+2);
						  ZION.DISPLAY_Config = *(zionHeaderData+3);
					  }
					  ZION.zionFinished=1;
					  osThreadExit();
				  }
			  }
		  }
	  }
	  else{
		  //should never get here but added for completeness
		  osThreadExit();
	  }
    osDelay(400);
  }
  /* USER CODE END startZionRead */
}

void startBootButtons(void *argument)
{
  /* USER CODE BEGIN startBootButtons */
  /* Infinite loop */
	int pwrBtnReady=0;
	int timeTurnedOn=0;
	int presentTime=0;
  for(;;)
  {
	  if(bootButtons.bootModeSet){
		  int weAreAtlas = (ZION.SOC_BoardFab == ATLAS) || (ZION.ASIC_BoardFab == ATLAS) || (ZION.DISPLAY_BoardFab == ATLAS);
		  presentTime = (HAL_GetTick());
		  if(timeTurnedOn==0){
			  timeTurnedOn=presentTime;
		  }
		  if(weAreAtlas){
			  pwrBtnReady=atlasBootButtons(pwrBtnReady);
		  }
		  else{
			  pwrBtnReady=defaultBootButtons(pwrBtnReady);
		  }
	  }
    osDelay(800);
  }
  /* USER CODE END startBootButtons */
}

void startSocUart(void *argument)
{
  /* USER CODE BEGIN startSocUart */
	uint8_t * receivedBytes;
	uint8_t values[11];
  /* Infinite loop */
  for(;;)
  {
	  receivedBytes = socUartParser();
	  if((*receivedBytes) != 0xff){
		  for(int x=4;x<15;x++){
			  values[x-4] = *(receivedBytes+x);
		  }
	  }
	  //int x = 0;
    osDelay(400);
  }
  /* USER CODE END startSocUart */
}

void startDebugUart(void *argument)
{
  /* USER CODE BEGIN startDebugUart */
	uint8_t commandSent;
	int x;
  /* Infinite loop */
	float * presentADCValues;
	float adcValues[21];

  for(;;)
  {
	  if(ADC_FINISHED){
		  presentADCValues = getADCValues();

	  }
	  commandSent = debugUartParser();
	  if(commandSent == true){
		  char buf[5];
		  debugUartTransmitChar("ADCValues:");
		  for(x=0;x<21;x++){
			  adcValues[x]=*(presentADCValues+x);
			  sprintf(buf, "%f", adcValues[x]);
			  //snprintf(buf, 5, "%f", *(presentADCValues+x));
			  debugUartTransmitStuff(buf,5);
			  if(x<20){
				  debugUartTransmitChar(",");
			  }

		  }
		  debugUartTransmitChar("\r\n");
		  debugUartTransmitChar("INPUT GPIOs:");
		  //uint8_t gpioInputs[12];
		  //memcpy(gpioInputs,gpioInputBuf,sizeof(gpioInputBuf));
		  for(x=0;x<sizeof(gpioInputBuf);x++){
			  sprintf(buf,"%x",gpioInputBuf[x]);
			  debugUartTransmitChar(buf);
			  if(x<(sizeof(gpioInputBuf))-1){
				  debugUartTransmitChar(",");
			  }
		  }
		  //HAL_UART_Transmit(&DEBUG_UART,(uint8_t *)gpioInputs, sizeof(gpioInputs),100);
		  debugUartTransmitChar("\r\n");
		  debugUartTransmitChar("Errors:");
		  uint8_t errors[11];
		  errors[0] = errorLED.zionFault;
		  errors[1] = errorLED.vsysPMIFault;
		  errors[2] = errorLED.fault3;
		  errors[3] = errorLED.fault4;
		  errors[4] = errorLED.fault5;
		  errors[5] = errorLED.fault6;
		  errors[6] = errorLED.fault7;
		  errors[7] = errorLED.fault8;
		  errors[8] = errorLED.fault9;
		  errors[9] = errorLED.boot_fault;
		  errors[10] = errorLED.ledDriver;
		  for(x=0;x<sizeof(errors);x++){
			  sprintf(buf,"%x",errors[x]);
			  debugUartTransmitChar(buf);
			  if(x<(sizeof(errors))-1){
				  debugUartTransmitChar(",");
			  }
		  }
		  debugUartTransmitChar("\r\n");
		  debugUartTransmitChar("Boot Mode:");
		  sprintf(buf,"%d",bootButtons.bootMode);
		  debugUartTransmitChar(buf);
		  //HAL_UART_Transmit(&DEBUG_UART,(uint8_t *)bootButtons.bootMode, 1,100);
		  debugUartTransmitChar("\r\n");
		  uint8_t zionInfo[9];
		  debugUartTransmitChar("Zion Info:");
		  zionInfo[0] = ZION.SOC_EEPROM_Detected;
		  zionInfo[1] = ZION.ASIC_EEPROM_Detected;
		  zionInfo[2] = ZION.DISPLAY_EEPROM_Detected;
		  zionInfo[3] = ZION.SOC_BoardID;
		  zionInfo[4] = ZION.ASIC_BoardID;
		  zionInfo[5] = ZION.DISPLAY_BoardID;
		  zionInfo[6] = ZION.SOC_BoardFab;
		  zionInfo[7] = ZION.ASIC_BoardFab;
		  zionInfo[8] = ZION.DISPLAY_BoardFab;
		  for(x=0;x<sizeof(zionInfo);x++){
			  sprintf(buf,"%x",zionInfo[x]);
			  debugUartTransmitChar(buf);
			  if(x<(sizeof(zionInfo))-1){
				  debugUartTransmitChar(",");
			  }
		 }
	  }
    osDelay(500);
  }
  /* USER CODE END startDebugUart */
}

 /**
  * @brief  Period elapsed callback in non blocking mode
  * @note   This function is called  when TIM6 interrupt took place, inside
  * HAL_TIM_IRQHandler(). It makes a direct call to HAL_IncTick() to increment
  * a global variable "uwTick" used as application time base.
  * @param  htim : TIM handle
  * @retval None
  */
void HAL_TIM_PeriodElapsedCallback(TIM_HandleTypeDef *htim)
{
  if (htim->Instance == TIM6) {
    HAL_IncTick();
  }
}

void Error_Handler(void)
{
  __disable_irq();
  while (1)
  {
  }
}

/************************ (C) COPYRIGHT STMicroelectronics *****END OF FILE****/
